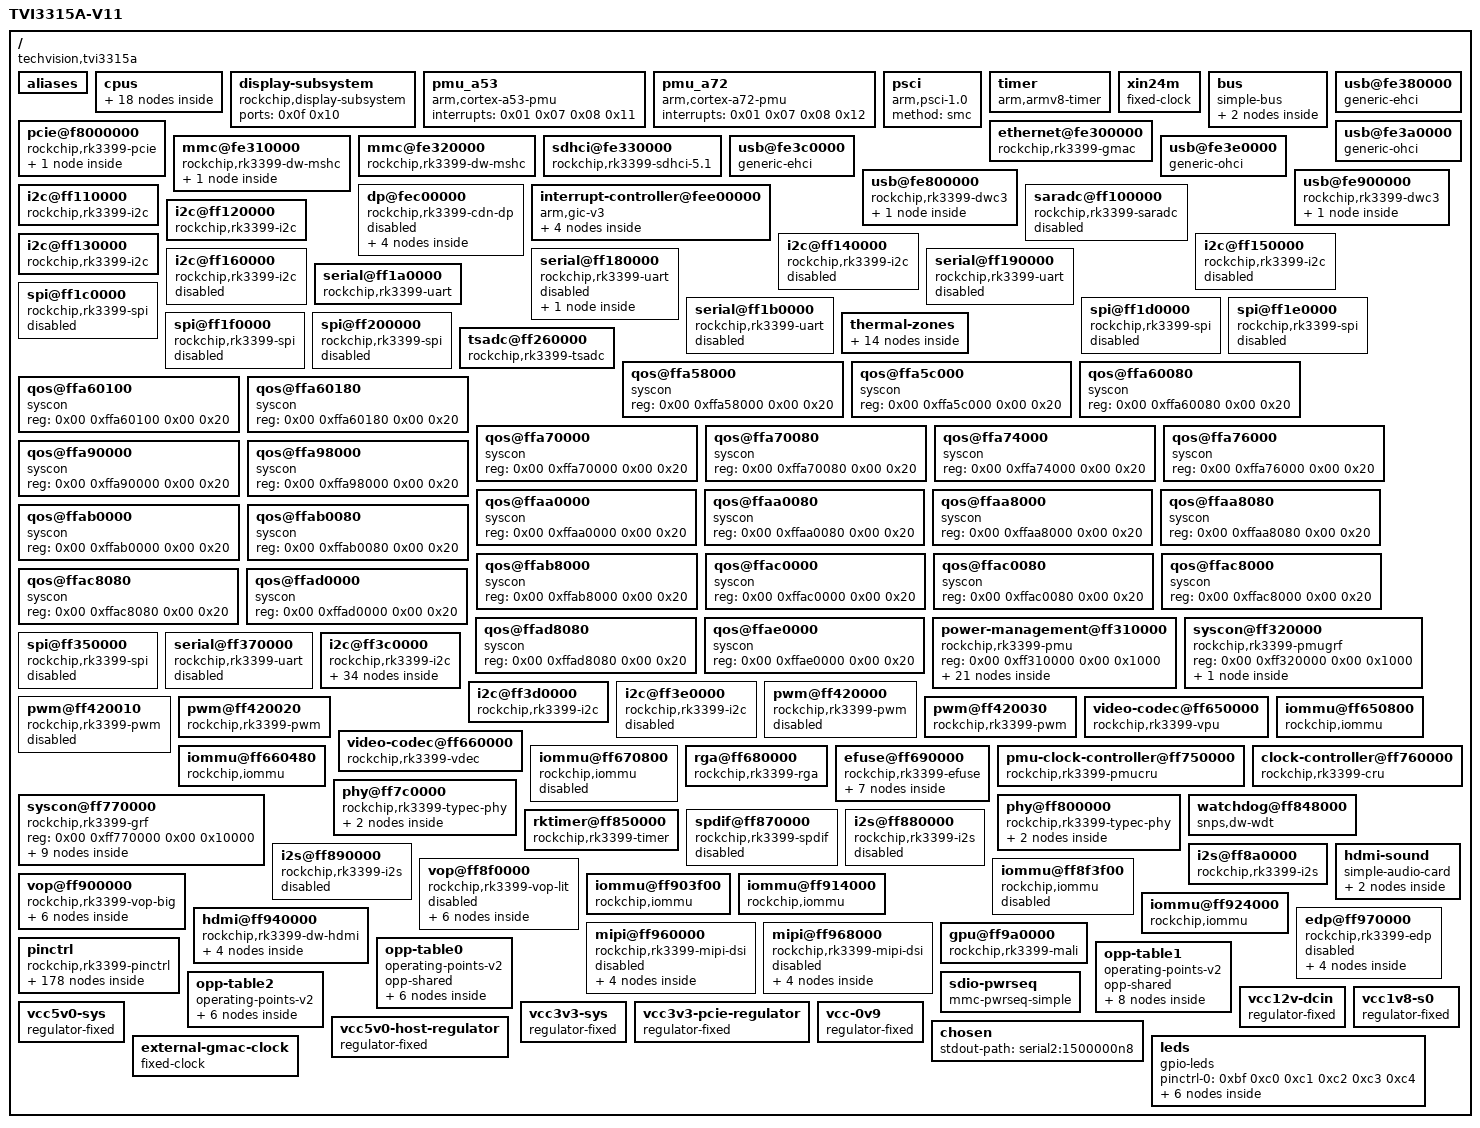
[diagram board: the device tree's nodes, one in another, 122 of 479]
/dts-v1/;

/ {
	compatible = "techvision,tvi3315a\0rockchip,rk3399";
	interrupt-parent = <0x01>;
	#address-cells = <0x02>;
	#size-cells = <0x02>;
	model = "TVI3315A-V11";

	aliases {
		ethernet0 = "/ethernet@fe300000";
		i2c0 = "/i2c@ff3c0000";
		i2c1 = "/i2c@ff110000";
		i2c2 = "/i2c@ff120000";
		i2c3 = "/i2c@ff130000";
		i2c4 = "/i2c@ff3d0000";
		i2c5 = "/i2c@ff140000";
		i2c6 = "/i2c@ff150000";
		i2c7 = "/i2c@ff160000";
		i2c8 = "/i2c@ff3e0000";
		serial0 = "/serial@ff180000";
		serial1 = "/serial@ff190000";
		serial2 = "/serial@ff1a0000";
		serial3 = "/serial@ff1b0000";
		serial4 = "/serial@ff370000";
	};

	cpus {
		#address-cells = <0x02>;
		#size-cells = <0x00>;

		cpu-map {

			cluster0 {

				core0 {
					cpu = <0x02>;
				};

				core1 {
					cpu = <0x03>;
				};

				core2 {
					cpu = <0x04>;
				};

				core3 {
					cpu = <0x05>;
				};
			};

			cluster1 {

				core0 {
					cpu = <0x06>;
				};

				core1 {
					cpu = <0x07>;
				};
			};
		};

		cpu@0 {
			device_type = "cpu";
			compatible = "arm,cortex-a53";
			reg = <0x00 0x00>;
			enable-method = "psci";
			capacity-dmips-mhz = <0x1e5>;
			clocks = <0x08 0x08>;
			#cooling-cells = <0x02>;
			dynamic-power-coefficient = <0x64>;
			cpu-idle-states = <0x09 0x0a>;
			operating-points-v2 = <0x0b>;
			cpu-supply = <0x0c>;
			phandle = <0x02>;
		};

		cpu@1 {
			device_type = "cpu";
			compatible = "arm,cortex-a53";
			reg = <0x00 0x01>;
			enable-method = "psci";
			capacity-dmips-mhz = <0x1e5>;
			clocks = <0x08 0x08>;
			#cooling-cells = <0x02>;
			dynamic-power-coefficient = <0x64>;
			cpu-idle-states = <0x09 0x0a>;
			operating-points-v2 = <0x0b>;
			cpu-supply = <0x0c>;
			phandle = <0x03>;
		};

		cpu@2 {
			device_type = "cpu";
			compatible = "arm,cortex-a53";
			reg = <0x00 0x02>;
			enable-method = "psci";
			capacity-dmips-mhz = <0x1e5>;
			clocks = <0x08 0x08>;
			#cooling-cells = <0x02>;
			dynamic-power-coefficient = <0x64>;
			cpu-idle-states = <0x09 0x0a>;
			operating-points-v2 = <0x0b>;
			cpu-supply = <0x0c>;
			phandle = <0x04>;
		};

		cpu@3 {
			device_type = "cpu";
			compatible = "arm,cortex-a53";
			reg = <0x00 0x03>;
			enable-method = "psci";
			capacity-dmips-mhz = <0x1e5>;
			clocks = <0x08 0x08>;
			#cooling-cells = <0x02>;
			dynamic-power-coefficient = <0x64>;
			cpu-idle-states = <0x09 0x0a>;
			operating-points-v2 = <0x0b>;
			cpu-supply = <0x0c>;
			phandle = <0x05>;
		};

		cpu@100 {
			device_type = "cpu";
			compatible = "arm,cortex-a72";
			reg = <0x00 0x100>;
			enable-method = "psci";
			capacity-dmips-mhz = <0x400>;
			clocks = <0x08 0x09>;
			#cooling-cells = <0x02>;
			dynamic-power-coefficient = <0x1b4>;
			cpu-idle-states = <0x09 0x0a>;
			operating-points-v2 = <0x0d>;
			cpu-supply = <0x0e>;
			phandle = <0x06>;
		};

		cpu@101 {
			device_type = "cpu";
			compatible = "arm,cortex-a72";
			reg = <0x00 0x101>;
			enable-method = "psci";
			capacity-dmips-mhz = <0x400>;
			clocks = <0x08 0x09>;
			#cooling-cells = <0x02>;
			dynamic-power-coefficient = <0x1b4>;
			cpu-idle-states = <0x09 0x0a>;
			operating-points-v2 = <0x0d>;
			cpu-supply = <0x0e>;
			phandle = <0x07>;
		};

		idle-states {
			entry-method = "psci";

			cpu-sleep {
				compatible = "arm,idle-state";
				local-timer-stop;
				arm,psci-suspend-param = <0x10000>;
				entry-latency-us = <0x78>;
				exit-latency-us = <0xfa>;
				min-residency-us = <0x384>;
				phandle = <0x09>;
			};

			cluster-sleep {
				compatible = "arm,idle-state";
				local-timer-stop;
				arm,psci-suspend-param = <0x1010000>;
				entry-latency-us = <0x190>;
				exit-latency-us = <0x1f4>;
				min-residency-us = <0x7d0>;
				phandle = <0x0a>;
			};
		};
	};

	display-subsystem {
		compatible = "rockchip,display-subsystem";
		ports = <0x0f 0x10>;
	};

	pmu_a53 {
		compatible = "arm,cortex-a53-pmu";
		interrupts = <0x01 0x07 0x08 0x11>;
	};

	pmu_a72 {
		compatible = "arm,cortex-a72-pmu";
		interrupts = <0x01 0x07 0x08 0x12>;
	};

	psci {
		compatible = "arm,psci-1.0";
		method = "smc";
	};

	timer {
		compatible = "arm,armv8-timer";
		interrupts = <0x01 0x0d 0x08 0x00 0x01 0x0e 0x08 0x00 0x01 0x0b 0x08 0x00 0x01 0x0a 0x08 0x00>;
		arm,no-tick-in-suspend;
	};

	xin24m {
		compatible = "fixed-clock";
		clock-frequency = <0x16e3600>;
		clock-output-names = "xin24m";
		#clock-cells = <0x00>;
	};

	bus {
		compatible = "simple-bus";
		#address-cells = <0x02>;
		#size-cells = <0x02>;
		ranges;

		dma-controller@ff6d0000 {
			compatible = "arm,pl330\0arm,primecell";
			reg = <0x00 0xff6d0000 0x00 0x4000>;
			interrupts = <0x00 0x05 0x04 0x00 0x00 0x06 0x04 0x00>;
			#dma-cells = <0x01>;
			clocks = <0x08 0xd3>;
			clock-names = "apb_pclk";
			phandle = <0x5a>;
		};

		dma-controller@ff6e0000 {
			compatible = "arm,pl330\0arm,primecell";
			reg = <0x00 0xff6e0000 0x00 0x4000>;
			interrupts = <0x00 0x07 0x04 0x00 0x00 0x08 0x04 0x00>;
			#dma-cells = <0x01>;
			clocks = <0x08 0xd4>;
			clock-names = "apb_pclk";
			phandle = <0x49>;
		};
	};

	pcie@f8000000 {
		compatible = "rockchip,rk3399-pcie";
		reg = <0x00 0xf8000000 0x00 0x2000000 0x00 0xfd000000 0x00 0x1000000>;
		reg-names = "axi-base\0apb-base";
		#address-cells = <0x03>;
		#size-cells = <0x02>;
		#interrupt-cells = <0x01>;
		aspm-no-l0s;
		bus-range = <0x00 0x1f>;
		clocks = <0x08 0xc5 0x08 0xc4 0x08 0x147 0x08 0xa0>;
		clock-names = "aclk\0aclk-perf\0hclk\0pm";
		interrupts = <0x00 0x31 0x04 0x00 0x00 0x32 0x04 0x00 0x00 0x33 0x04 0x00>;
		interrupt-names = "sys\0legacy\0client";
		interrupt-map-mask = <0x00 0x00 0x00 0x07>;
		interrupt-map = <0x00 0x00 0x00 0x01 0x13 0x00 0x00 0x00 0x00 0x02 0x13 0x01 0x00 0x00 0x00 0x03 0x13 0x02 0x00 0x00 0x00 0x04 0x13 0x03>;
		linux,pci-domain = <0x00>;
		max-link-speed = <0x01>;
		msi-map = <0x00 0x14 0x00 0x1000>;
		phys = <0x15 0x00 0x15 0x01 0x15 0x02 0x15 0x03>;
		phy-names = "pcie-phy-0\0pcie-phy-1\0pcie-phy-2\0pcie-phy-3";
		ranges = <0x83000000 0x00 0xfa000000 0x00 0xfa000000 0x00 0x1e00000 0x81000000 0x00 0xfbe00000 0x00 0xfbe00000 0x00 0x100000>;
		resets = <0x08 0x82 0x08 0x83 0x08 0x84 0x08 0x85 0x08 0x86 0x08 0x81 0x08 0x80>;
		reset-names = "core\0mgmt\0mgmt-sticky\0pipe\0pm\0pclk\0aclk";
		status = "okay";
		num-lanes = <0x04>;
		pinctrl-names = "default";
		pinctrl-0 = <0x16>;
		vpcie0v9-supply = <0x17>;
		vpcie1v8-supply = <0x18>;
		vpcie3v3-supply = <0x19>;
		ep-gpios = <0x1a 0x02 0x00>;

		interrupt-controller {
			interrupt-controller;
			#address-cells = <0x00>;
			#interrupt-cells = <0x01>;
			phandle = <0x13>;
		};
	};

	ethernet@fe300000 {
		compatible = "rockchip,rk3399-gmac";
		reg = <0x00 0xfe300000 0x00 0x10000>;
		interrupts = <0x00 0x0c 0x04 0x00>;
		interrupt-names = "macirq";
		clocks = <0x08 0x69 0x08 0x67 0x08 0x68 0x08 0x66 0x08 0x6a 0x08 0xd5 0x08 0x166>;
		clock-names = "stmmaceth\0mac_clk_rx\0mac_clk_tx\0clk_mac_ref\0clk_mac_refout\0aclk_mac\0pclk_mac";
		power-domains = <0x1b 0x16>;
		resets = <0x08 0x89>;
		reset-names = "stmmaceth";
		rockchip,grf = <0x1c>;
		snps,txpbl = <0x04>;
		status = "okay";
		assigned-clocks = <0x08 0xa6>;
		assigned-clock-parents = <0x1d>;
		clock_in_out = "input";
		phy-supply = <0x1e>;
		phy-mode = "rgmii";
		pinctrl-names = "default";
		pinctrl-0 = <0x1f>;
		snps,reset-gpio = <0x20 0x0f 0x01>;
		snps,reset-active-low;
		snps,reset-delays-us = <0x00 0x2710 0xc350>;
		tx_delay = <0x2a>;
		rx_delay = <0x21>;
	};

	mmc@fe310000 {
		compatible = "rockchip,rk3399-dw-mshc\0rockchip,rk3288-dw-mshc";
		reg = <0x00 0xfe310000 0x00 0x4000>;
		interrupts = <0x00 0x40 0x04 0x00>;
		max-frequency = <0x8f0d180>;
		clocks = <0x08 0x1ee 0x08 0x4d 0x08 0x9c 0x08 0x9d>;
		clock-names = "biu\0ciu\0ciu-drive\0ciu-sample";
		fifo-depth = <0x100>;
		power-domains = <0x1b 0x1c>;
		resets = <0x08 0x79>;
		reset-names = "reset";
		status = "okay";
		bus-width = <0x04>;
		clock-frequency = <0x2faf080>;
		cap-sdio-irq;
		cap-sd-highspeed;
		keep-power-in-suspend;
		mmc-pwrseq = <0x21>;
		non-removable;
		pinctrl-names = "default";
		pinctrl-0 = <0x22 0x23 0x24>;
		sd-uhs-sdr104;
		#address-cells = <0x01>;
		#size-cells = <0x00>;

		wifi@1 {
			compatible = "brcm,bcm43455-fmac";
			reg = <0x01>;
			interrupt-parent = <0x25>;
			interrupts = <0x03 0x00>;
			interrupt-names = "host-wake";
			pinctrl-names = "default";
			pinctrl-0 = <0x26>;
		};
	};

	mmc@fe320000 {
		compatible = "rockchip,rk3399-dw-mshc\0rockchip,rk3288-dw-mshc";
		reg = <0x00 0xfe320000 0x00 0x4000>;
		interrupts = <0x00 0x41 0x04 0x00>;
		max-frequency = <0x5f5e100>;
		assigned-clocks = <0x08 0x1cd>;
		assigned-clock-rates = <0xbebc200>;
		clocks = <0x08 0x1ce 0x08 0x4c 0x08 0x9a 0x08 0x9b>;
		clock-names = "biu\0ciu\0ciu-drive\0ciu-sample";
		fifo-depth = <0x100>;
		power-domains = <0x1b 0x1b>;
		resets = <0x08 0x7a>;
		reset-names = "reset";
		status = "okay";
		bus-width = <0x04>;
		cap-mmc-highspeed;
		cap-sd-highspeed;
		clock-frequency = <0x5f5e100>;
		cd-gpios = <0x25 0x07 0x01>;
		disable-wp;
		sd-uhs-sdr104;
		vqmmc-supply = <0x27>;
		card-detect-delay = <0x320>;
		pinctrl-names = "default";
		pinctrl-0 = <0x28 0x29 0x2a 0x2b>;
	};

	sdhci@fe330000 {
		compatible = "rockchip,rk3399-sdhci-5.1\0arasan,sdhci-5.1";
		reg = <0x00 0xfe330000 0x00 0x10000>;
		interrupts = <0x00 0x0b 0x04 0x00>;
		arasan,soc-ctl-syscon = <0x1c>;
		assigned-clocks = <0x08 0x4e>;
		assigned-clock-rates = <0xbebc200>;
		clocks = <0x08 0x4e 0x08 0xf0>;
		clock-names = "clk_xin\0clk_ahb";
		clock-output-names = "emmc_cardclock";
		#clock-cells = <0x00>;
		phys = <0x2c>;
		phy-names = "phy_arasan";
		power-domains = <0x1b 0x17>;
		disable-cqe-dcmd;
		status = "okay";
		bus-width = <0x08>;
		mmc-hs400-1_8v;
		mmc-hs400-enhanced-strobe;
		non-removable;
		phandle = <0x91>;
	};

	usb@fe380000 {
		compatible = "generic-ehci";
		reg = <0x00 0xfe380000 0x00 0x20000>;
		interrupts = <0x00 0x1a 0x04 0x00>;
		clocks = <0x08 0x1c8 0x08 0x1c9 0x2d>;
		phys = <0x2e>;
		phy-names = "usb";
		status = "okay";
	};

	usb@fe3a0000 {
		compatible = "generic-ohci";
		reg = <0x00 0xfe3a0000 0x00 0x20000>;
		interrupts = <0x00 0x1c 0x04 0x00>;
		clocks = <0x08 0x1c8 0x08 0x1c9 0x2d>;
		phys = <0x2e>;
		phy-names = "usb";
		status = "okay";
	};

	usb@fe3c0000 {
		compatible = "generic-ehci";
		reg = <0x00 0xfe3c0000 0x00 0x20000>;
		interrupts = <0x00 0x1e 0x04 0x00>;
		clocks = <0x08 0x1ca 0x08 0x1cb 0x2f>;
		phys = <0x30>;
		phy-names = "usb";
		status = "okay";
	};

	usb@fe3e0000 {
		compatible = "generic-ohci";
		reg = <0x00 0xfe3e0000 0x00 0x20000>;
		interrupts = <0x00 0x20 0x04 0x00>;
		clocks = <0x08 0x1ca 0x08 0x1cb 0x2f>;
		phys = <0x30>;
		phy-names = "usb";
		status = "okay";
	};

	usb@fe800000 {
		compatible = "rockchip,rk3399-dwc3";
		#address-cells = <0x02>;
		#size-cells = <0x02>;
		ranges;
		clocks = <0x08 0x81 0x08 0x83 0x08 0xf6 0x08 0xf8 0x08 0xf4 0x08 0xf9>;
		clock-names = "ref_clk\0suspend_clk\0bus_clk\0aclk_usb3_rksoc_axi_perf\0aclk_usb3\0grf_clk";
		resets = <0x08 0x125>;
		reset-names = "usb3-otg";
		status = "okay";

		usb@fe800000 {
			compatible = "snps,dwc3";
			reg = <0x00 0xfe800000 0x00 0x100000>;
			interrupts = <0x00 0x69 0x04 0x00>;
			clocks = <0x08 0x81 0x08 0xf6 0x08 0x83>;
			clock-names = "ref\0bus_early\0suspend";
			dr_mode = "host";
			phys = <0x31 0x32>;
			phy-names = "usb2-phy\0usb3-phy";
			phy_type = "utmi_wide";
			snps,dis_enblslpm_quirk;
			snps,dis-u2-freeclk-exists-quirk;
			snps,dis_u2_susphy_quirk;
			snps,dis-del-phy-power-chg-quirk;
			snps,dis-tx-ipgap-linecheck-quirk;
			power-domains = <0x1b 0x18>;
			status = "okay";
		};
	};

	usb@fe900000 {
		compatible = "rockchip,rk3399-dwc3";
		#address-cells = <0x02>;
		#size-cells = <0x02>;
		ranges;
		clocks = <0x08 0x82 0x08 0x84 0x08 0xf7 0x08 0xf8 0x08 0xf4 0x08 0xf9>;
		clock-names = "ref_clk\0suspend_clk\0bus_clk\0aclk_usb3_rksoc_axi_perf\0aclk_usb3\0grf_clk";
		resets = <0x08 0x126>;
		reset-names = "usb3-otg";
		status = "okay";

		usb@fe900000 {
			compatible = "snps,dwc3";
			reg = <0x00 0xfe900000 0x00 0x100000>;
			interrupts = <0x00 0x6e 0x04 0x00>;
			clocks = <0x08 0x82 0x08 0xf7 0x08 0x84>;
			clock-names = "ref\0bus_early\0suspend";
			dr_mode = "host";
			phys = <0x33 0x34>;
			phy-names = "usb2-phy\0usb3-phy";
			phy_type = "utmi_wide";
			snps,dis_enblslpm_quirk;
			snps,dis-u2-freeclk-exists-quirk;
			snps,dis_u2_susphy_quirk;
			snps,dis-del-phy-power-chg-quirk;
			snps,dis-tx-ipgap-linecheck-quirk;
			power-domains = <0x1b 0x18>;
			status = "okay";
		};
	};

	dp@fec00000 {
		compatible = "rockchip,rk3399-cdn-dp";
		reg = <0x00 0xfec00000 0x00 0x100000>;
		interrupts = <0x00 0x09 0x04 0x00>;
		assigned-clocks = <0x08 0x72 0x08 0xa1>;
		assigned-clock-rates = <0x5f5e100 0xbebc200>;
		clocks = <0x08 0x72 0x08 0x175 0x08 0xa1 0x08 0x16f>;
		clock-names = "core-clk\0pclk\0spdif\0grf";
		phys = <0x35 0x36>;
		power-domains = <0x1b 0x15>;
		resets = <0x08 0x103 0x08 0x148 0x08 0x14a 0x08 0xfd>;
		reset-names = "spdif\0dptx\0apb\0core";
		rockchip,grf = <0x1c>;
		#sound-dai-cells = <0x01>;
		status = "disabled";

		ports {

			port {
				#address-cells = <0x01>;
				#size-cells = <0x00>;

				endpoint@0 {
					reg = <0x00>;
					remote-endpoint = <0x37>;
					phandle = <0xa0>;
				};

				endpoint@1 {
					reg = <0x01>;
					remote-endpoint = <0x38>;
					phandle = <0x9a>;
				};
			};
		};
	};

	interrupt-controller@fee00000 {
		compatible = "arm,gic-v3";
		#interrupt-cells = <0x04>;
		#address-cells = <0x02>;
		#size-cells = <0x02>;
		ranges;
		interrupt-controller;
		reg = <0x00 0xfee00000 0x00 0x10000 0x00 0xfef00000 0x00 0xc0000 0x00 0xfff00000 0x00 0x10000 0x00 0xfff10000 0x00 0x10000 0x00 0xfff20000 0x00 0x10000>;
		interrupts = <0x01 0x09 0x04 0x00>;
		phandle = <0x01>;

		interrupt-controller@fee20000 {
			compatible = "arm,gic-v3-its";
			msi-controller;
			#msi-cells = <0x01>;
			reg = <0x00 0xfee20000 0x00 0x20000>;
			phandle = <0x14>;
		};

		ppi-partitions {

			interrupt-partition-0 {
				affinity = <0x02 0x03 0x04 0x05>;
				phandle = <0x11>;
			};

			interrupt-partition-1 {
				affinity = <0x06 0x07>;
				phandle = <0x12>;
			};
		};
	};

	saradc@ff100000 {
		compatible = "rockchip,rk3399-saradc";
		reg = <0x00 0xff100000 0x00 0x100>;
		interrupts = <0x00 0x3e 0x04 0x00>;
		#io-channel-cells = <0x01>;
		clocks = <0x08 0x50 0x08 0x165>;
		clock-names = "saradc\0apb_pclk";
		resets = <0x08 0xd4>;
		reset-names = "saradc-apb";
		status = "disabled";
	};

	i2c@ff110000 {
		compatible = "rockchip,rk3399-i2c";
		reg = <0x00 0xff110000 0x00 0x1000>;
		assigned-clocks = <0x08 0x41>;
		assigned-clock-rates = <0xbebc200>;
		clocks = <0x08 0x41 0x08 0x155>;
		clock-names = "i2c\0pclk";
		interrupts = <0x00 0x3b 0x04 0x00>;
		pinctrl-names = "default";
		pinctrl-0 = <0x39>;
		#address-cells = <0x01>;
		#size-cells = <0x00>;
		status = "okay";
	};

	i2c@ff120000 {
		compatible = "rockchip,rk3399-i2c";
		reg = <0x00 0xff120000 0x00 0x1000>;
		assigned-clocks = <0x08 0x42>;
		assigned-clock-rates = <0xbebc200>;
		clocks = <0x08 0x42 0x08 0x156>;
		clock-names = "i2c\0pclk";
		interrupts = <0x00 0x23 0x04 0x00>;
		pinctrl-names = "default";
		pinctrl-0 = <0x3a>;
		#address-cells = <0x01>;
		#size-cells = <0x00>;
		status = "okay";
	};

	i2c@ff130000 {
		compatible = "rockchip,rk3399-i2c";
		reg = <0x00 0xff130000 0x00 0x1000>;
		assigned-clocks = <0x08 0x43>;
		assigned-clock-rates = <0xbebc200>;
		clocks = <0x08 0x43 0x08 0x157>;
		clock-names = "i2c\0pclk";
		interrupts = <0x00 0x22 0x04 0x00>;
		pinctrl-names = "default";
		pinctrl-0 = <0x3b>;
		#address-cells = <0x01>;
		#size-cells = <0x00>;
		status = "okay";
		phandle = <0xa3>;
	};

	i2c@ff140000 {
		compatible = "rockchip,rk3399-i2c";
		reg = <0x00 0xff140000 0x00 0x1000>;
		assigned-clocks = <0x08 0x44>;
		assigned-clock-rates = <0xbebc200>;
		clocks = <0x08 0x44 0x08 0x158>;
		clock-names = "i2c\0pclk";
		interrupts = <0x00 0x26 0x04 0x00>;
		pinctrl-names = "default";
		pinctrl-0 = <0x3c>;
		#address-cells = <0x01>;
		#size-cells = <0x00>;
		status = "disabled";
	};

	i2c@ff150000 {
		compatible = "rockchip,rk3399-i2c";
		reg = <0x00 0xff150000 0x00 0x1000>;
		assigned-clocks = <0x08 0x45>;
		assigned-clock-rates = <0xbebc200>;
		clocks = <0x08 0x45 0x08 0x159>;
		clock-names = "i2c\0pclk";
		interrupts = <0x00 0x25 0x04 0x00>;
		pinctrl-names = "default";
		pinctrl-0 = <0x3d>;
		#address-cells = <0x01>;
		#size-cells = <0x00>;
		status = "disabled";
	};

	i2c@ff160000 {
		compatible = "rockchip,rk3399-i2c";
		reg = <0x00 0xff160000 0x00 0x1000>;
		assigned-clocks = <0x08 0x46>;
		assigned-clock-rates = <0xbebc200>;
		clocks = <0x08 0x46 0x08 0x15a>;
		clock-names = "i2c\0pclk";
		interrupts = <0x00 0x24 0x04 0x00>;
		pinctrl-names = "default";
		pinctrl-0 = <0x3e>;
		#address-cells = <0x01>;
		#size-cells = <0x00>;
		status = "disabled";
	};

	serial@ff180000 {
		compatible = "rockchip,rk3399-uart\0snps,dw-apb-uart";
		reg = <0x00 0xff180000 0x00 0x100>;
		clocks = <0x08 0x51 0x08 0x160>;
		clock-names = "baudclk\0apb_pclk";
		interrupts = <0x00 0x63 0x04 0x00>;
		reg-shift = <0x02>;
		reg-io-width = <0x04>;
		pinctrl-names = "default";
		pinctrl-0 = <0x3f 0x40 0x41>;
		status = "disabled";

		bluetooth {
			compatible = "brcm,bcm4345c5";
			clocks = <0x42 0x01>;
			clock-names = "ext_clock";
			device-wakeup-gpios = <0x1a 0x1b 0x00>;
			host-wakeup-gpios = <0x25 0x04 0x00>;
			shutdown-gpios = <0x25 0x0b 0x00>;
			max-speed = <0x16e360>;
			pinctrl-names = "default";
			pinctrl-0 = <0x43 0x44 0x45>;
		};
	};

	serial@ff190000 {
		compatible = "rockchip,rk3399-uart\0snps,dw-apb-uart";
		reg = <0x00 0xff190000 0x00 0x100>;
		clocks = <0x08 0x52 0x08 0x161>;
		clock-names = "baudclk\0apb_pclk";
		interrupts = <0x00 0x62 0x04 0x00>;
		reg-shift = <0x02>;
		reg-io-width = <0x04>;
		pinctrl-names = "default";
		pinctrl-0 = <0x46>;
		status = "disabled";
	};

	serial@ff1a0000 {
		compatible = "rockchip,rk3399-uart\0snps,dw-apb-uart";
		reg = <0x00 0xff1a0000 0x00 0x100>;
		clocks = <0x08 0x53 0x08 0x162>;
		clock-names = "baudclk\0apb_pclk";
		interrupts = <0x00 0x64 0x04 0x00>;
		reg-shift = <0x02>;
		reg-io-width = <0x04>;
		pinctrl-names = "default";
		pinctrl-0 = <0x47>;
		status = "okay";
	};

	serial@ff1b0000 {
		compatible = "rockchip,rk3399-uart\0snps,dw-apb-uart";
		reg = <0x00 0xff1b0000 0x00 0x100>;
		clocks = <0x08 0x54 0x08 0x163>;
		clock-names = "baudclk\0apb_pclk";
		interrupts = <0x00 0x65 0x04 0x00>;
		reg-shift = <0x02>;
		reg-io-width = <0x04>;
		pinctrl-names = "default";
		pinctrl-0 = <0x48>;
		status = "disabled";
	};

	spi@ff1c0000 {
		compatible = "rockchip,rk3399-spi\0rockchip,rk3066-spi";
		reg = <0x00 0xff1c0000 0x00 0x1000>;
		clocks = <0x08 0x47 0x08 0x15b>;
		clock-names = "spiclk\0apb_pclk";
		interrupts = <0x00 0x44 0x04 0x00>;
		dmas = <0x49 0x0a 0x49 0x0b>;
		dma-names = "tx\0rx";
		pinctrl-names = "default";
		pinctrl-0 = <0x4a 0x4b 0x4c 0x4d>;
		#address-cells = <0x01>;
		#size-cells = <0x00>;
		status = "disabled";
	};

	spi@ff1d0000 {
		compatible = "rockchip,rk3399-spi\0rockchip,rk3066-spi";
		reg = <0x00 0xff1d0000 0x00 0x1000>;
		clocks = <0x08 0x48 0x08 0x15c>;
		clock-names = "spiclk\0apb_pclk";
		interrupts = <0x00 0x35 0x04 0x00>;
		dmas = <0x49 0x0c 0x49 0x0d>;
		dma-names = "tx\0rx";
		pinctrl-names = "default";
		pinctrl-0 = <0x4e 0x4f 0x50 0x51>;
		#address-cells = <0x01>;
		#size-cells = <0x00>;
		status = "disabled";
	};

	spi@ff1e0000 {
		compatible = "rockchip,rk3399-spi\0rockchip,rk3066-spi";
		reg = <0x00 0xff1e0000 0x00 0x1000>;
		clocks = <0x08 0x49 0x08 0x15d>;
		clock-names = "spiclk\0apb_pclk";
		interrupts = <0x00 0x34 0x04 0x00>;
		dmas = <0x49 0x0e 0x49 0x0f>;
		dma-names = "tx\0rx";
		pinctrl-names = "default";
		pinctrl-0 = <0x52 0x53 0x54 0x55>;
		#address-cells = <0x01>;
		#size-cells = <0x00>;
		status = "disabled";
	};

	spi@ff1f0000 {
		compatible = "rockchip,rk3399-spi\0rockchip,rk3066-spi";
		reg = <0x00 0xff1f0000 0x00 0x1000>;
		clocks = <0x08 0x4a 0x08 0x15e>;
		clock-names = "spiclk\0apb_pclk";
		interrupts = <0x00 0x43 0x04 0x00>;
		dmas = <0x49 0x12 0x49 0x13>;
		dma-names = "tx\0rx";
		pinctrl-names = "default";
		pinctrl-0 = <0x56 0x57 0x58 0x59>;
		#address-cells = <0x01>;
		#size-cells = <0x00>;
		status = "disabled";
	};

	spi@ff200000 {
		compatible = "rockchip,rk3399-spi\0rockchip,rk3066-spi";
		reg = <0x00 0xff200000 0x00 0x1000>;
		clocks = <0x08 0x4b 0x08 0x15f>;
		clock-names = "spiclk\0apb_pclk";
		interrupts = <0x00 0x84 0x04 0x00>;
		dmas = <0x5a 0x08 0x5a 0x09>;
		dma-names = "tx\0rx";
		pinctrl-names = "default";
		pinctrl-0 = <0x5b 0x5c 0x5d 0x5e>;
		power-domains = <0x1b 0x1c>;
		#address-cells = <0x01>;
		#size-cells = <0x00>;
		status = "disabled";
	};

	thermal-zones {

		cpu {
			polling-delay-passive = <0x64>;
			polling-delay = <0x3e8>;
			thermal-sensors = <0x5f 0x00>;
			sustainable-power = <0x60e>;

			trips {

				cpu_alert0 {
					temperature = <0xfde8>;
					hysteresis = <0x7d0>;
					type = "passive";
				};

				cpu_alert1 {
					temperature = <0x124f8>;
					hysteresis = <0x7d0>;
					type = "passive";
					phandle = <0x60>;
				};

				cpu_crit {
					temperature = <0x17318>;
					hysteresis = <0x7d0>;
					type = "critical";
				};
			};

			cooling-maps {

				map0 {
					trip = <0x60>;
					cooling-device = <0x06 0xffffffff 0xffffffff 0x07 0xffffffff 0xffffffff>;
				};

				map1 {
					trip = <0x60>;
					cooling-device = <0x02 0xffffffff 0xffffffff 0x03 0xffffffff 0xffffffff 0x04 0xffffffff 0xffffffff 0x05 0xffffffff 0xffffffff 0x06 0xffffffff 0xffffffff 0x07 0xffffffff 0xffffffff>;
				};
			};
		};

		gpu {
			polling-delay-passive = <0x64>;
			polling-delay = <0x3e8>;
			thermal-sensors = <0x5f 0x01>;

			trips {

				gpu_alert0 {
					temperature = <0x124f8>;
					hysteresis = <0x7d0>;
					type = "passive";
					phandle = <0x61>;
				};

				gpu_crit {
					temperature = <0x17318>;
					hysteresis = <0x7d0>;
					type = "critical";
				};
			};

			cooling-maps {

				map0 {
					trip = <0x61>;
					cooling-device = <0x62 0xffffffff 0xffffffff>;
				};
			};
		};
	};

	tsadc@ff260000 {
		compatible = "rockchip,rk3399-tsadc";
		reg = <0x00 0xff260000 0x00 0x100>;
		interrupts = <0x00 0x61 0x04 0x00>;
		assigned-clocks = <0x08 0x4f>;
		assigned-clock-rates = <0xb71b0>;
		clocks = <0x08 0x4f 0x08 0x164>;
		clock-names = "tsadc\0apb_pclk";
		resets = <0x08 0xe8>;
		reset-names = "tsadc-apb";
		rockchip,grf = <0x1c>;
		rockchip,hw-tshut-temp = <0x1adb0>;
		pinctrl-names = "init\0default\0sleep";
		pinctrl-0 = <0x63>;
		pinctrl-1 = <0x64>;
		pinctrl-2 = <0x63>;
		#thermal-sensor-cells = <0x01>;
		status = "okay";
		rockchip,hw-tshut-mode = <0x01>;
		rockchip,hw-tshut-polarity = <0x01>;
		phandle = <0x5f>;
	};

	qos@ffa58000 {
		compatible = "syscon";
		reg = <0x00 0xffa58000 0x00 0x20>;
		phandle = <0x6c>;
	};

	qos@ffa5c000 {
		compatible = "syscon";
		reg = <0x00 0xffa5c000 0x00 0x20>;
		phandle = <0x6d>;
	};

	qos@ffa60080 {
		compatible = "syscon";
		reg = <0x00 0xffa60080 0x00 0x20>;
	};

	qos@ffa60100 {
		compatible = "syscon";
		reg = <0x00 0xffa60100 0x00 0x20>;
	};

	qos@ffa60180 {
		compatible = "syscon";
		reg = <0x00 0xffa60180 0x00 0x20>;
	};

	qos@ffa70000 {
		compatible = "syscon";
		reg = <0x00 0xffa70000 0x00 0x20>;
		phandle = <0x70>;
	};

	qos@ffa70080 {
		compatible = "syscon";
		reg = <0x00 0xffa70080 0x00 0x20>;
		phandle = <0x71>;
	};

	qos@ffa74000 {
		compatible = "syscon";
		reg = <0x00 0xffa74000 0x00 0x20>;
		phandle = <0x6e>;
	};

	qos@ffa76000 {
		compatible = "syscon";
		reg = <0x00 0xffa76000 0x00 0x20>;
		phandle = <0x6f>;
	};

	qos@ffa90000 {
		compatible = "syscon";
		reg = <0x00 0xffa90000 0x00 0x20>;
		phandle = <0x72>;
	};

	qos@ffa98000 {
		compatible = "syscon";
		reg = <0x00 0xffa98000 0x00 0x20>;
		phandle = <0x65>;
	};

	qos@ffaa0000 {
		compatible = "syscon";
		reg = <0x00 0xffaa0000 0x00 0x20>;
		phandle = <0x73>;
	};

	qos@ffaa0080 {
		compatible = "syscon";
		reg = <0x00 0xffaa0080 0x00 0x20>;
		phandle = <0x74>;
	};

	qos@ffaa8000 {
		compatible = "syscon";
		reg = <0x00 0xffaa8000 0x00 0x20>;
		phandle = <0x75>;
	};

	qos@ffaa8080 {
		compatible = "syscon";
		reg = <0x00 0xffaa8080 0x00 0x20>;
		phandle = <0x76>;
	};

	qos@ffab0000 {
		compatible = "syscon";
		reg = <0x00 0xffab0000 0x00 0x20>;
		phandle = <0x66>;
	};

	qos@ffab0080 {
		compatible = "syscon";
		reg = <0x00 0xffab0080 0x00 0x20>;
		phandle = <0x67>;
	};

	qos@ffab8000 {
		compatible = "syscon";
		reg = <0x00 0xffab8000 0x00 0x20>;
		phandle = <0x68>;
	};

	qos@ffac0000 {
		compatible = "syscon";
		reg = <0x00 0xffac0000 0x00 0x20>;
		phandle = <0x69>;
	};

	qos@ffac0080 {
		compatible = "syscon";
		reg = <0x00 0xffac0080 0x00 0x20>;
		phandle = <0x6a>;
	};

	qos@ffac8000 {
		compatible = "syscon";
		reg = <0x00 0xffac8000 0x00 0x20>;
		phandle = <0x77>;
	};

	qos@ffac8080 {
		compatible = "syscon";
		reg = <0x00 0xffac8080 0x00 0x20>;
		phandle = <0x78>;
	};

	qos@ffad0000 {
		compatible = "syscon";
		reg = <0x00 0xffad0000 0x00 0x20>;
		phandle = <0x79>;
	};

	qos@ffad8080 {
		compatible = "syscon";
		reg = <0x00 0xffad8080 0x00 0x20>;
	};

	qos@ffae0000 {
		compatible = "syscon";
		reg = <0x00 0xffae0000 0x00 0x20>;
		phandle = <0x6b>;
	};

	power-management@ff310000 {
		compatible = "rockchip,rk3399-pmu\0syscon\0simple-mfd";
		reg = <0x00 0xff310000 0x00 0x1000>;

		power-controller {
			compatible = "rockchip,rk3399-power-controller";
			#power-domain-cells = <0x01>;
			#address-cells = <0x01>;
			#size-cells = <0x00>;
			phandle = <0x1b>;

			pd_iep@34 {
				reg = <0x22>;
				clocks = <0x08 0xe1 0x08 0x1dd>;
				pm_qos = <0x65>;
			};

			pd_rga@33 {
				reg = <0x21>;
				clocks = <0x08 0xdc 0x08 0x1e5>;
				pm_qos = <0x66 0x67>;
			};

			pd_vcodec@31 {
				reg = <0x1f>;
				clocks = <0x08 0xeb 0x08 0x1ea>;
				pm_qos = <0x68>;
			};

			pd_vdu@32 {
				reg = <0x20>;
				clocks = <0x08 0xed 0x08 0x1ec>;
				pm_qos = <0x69 0x6a>;
			};

			pd_gpu@35 {
				reg = <0x23>;
				clocks = <0x08 0xd0>;
				pm_qos = <0x6b>;
			};

			pd_edp@25 {
				reg = <0x19>;
				clocks = <0x08 0x16c>;
			};

			pd_emmc@23 {
				reg = <0x17>;
				clocks = <0x08 0xf0>;
				pm_qos = <0x6c>;
			};

			pd_gmac@22 {
				reg = <0x16>;
				clocks = <0x08 0xd5 0x08 0x166>;
				pm_qos = <0x6d>;
			};

			pd_sd@27 {
				reg = <0x1b>;
				clocks = <0x08 0x1ce 0x08 0x4c>;
				pm_qos = <0x6e>;
			};

			pd_sdioaudio@28 {
				reg = <0x1c>;
				clocks = <0x08 0x1ee>;
				pm_qos = <0x6f>;
			};

			pd_usb3@24 {
				reg = <0x18>;
				clocks = <0x08 0xf4>;
				pm_qos = <0x70 0x71>;
			};

			pd_vio@15 {
				reg = <0x0f>;
				#address-cells = <0x01>;
				#size-cells = <0x00>;

				pd_hdcp@21 {
					reg = <0x15>;
					clocks = <0x08 0xde 0x08 0x1e7 0x08 0x172>;
					pm_qos = <0x72>;
				};

				pd_isp0@19 {
					reg = <0x13>;
					clocks = <0x08 0xe5 0x08 0x1df>;
					pm_qos = <0x73 0x74>;
				};

				pd_isp1@20 {
					reg = <0x14>;
					clocks = <0x08 0xe6 0x08 0x1e0>;
					pm_qos = <0x75 0x76>;
				};

				pd_tcpc0@RK3399_PD_TCPC0 {
					reg = <0x08>;
					clocks = <0x08 0x7e 0x08 0x7d>;
				};

				pd_tcpc1@RK3399_PD_TCPC1 {
					reg = <0x09>;
					clocks = <0x08 0x80 0x08 0x7f>;
				};

				pd_vo@16 {
					reg = <0x10>;
					#address-cells = <0x01>;
					#size-cells = <0x00>;

					pd_vopb@17 {
						reg = <0x11>;
						clocks = <0x08 0xd9 0x08 0x1d9>;
						pm_qos = <0x77 0x78>;
					};

					pd_vopl@18 {
						reg = <0x12>;
						clocks = <0x08 0xdb 0x08 0x1db>;
						pm_qos = <0x79>;
					};
				};
			};
		};
	};

	syscon@ff320000 {
		compatible = "rockchip,rk3399-pmugrf\0syscon\0simple-mfd";
		reg = <0x00 0xff320000 0x00 0x1000>;
		phandle = <0x8d>;

		io-domains {
			compatible = "rockchip,rk3399-pmu-io-voltage-domain";
			status = "okay";
			pmu1830-supply = <0x7a>;
		};
	};

	spi@ff350000 {
		compatible = "rockchip,rk3399-spi\0rockchip,rk3066-spi";
		reg = <0x00 0xff350000 0x00 0x1000>;
		clocks = <0x7b 0x03 0x7b 0x1f>;
		clock-names = "spiclk\0apb_pclk";
		interrupts = <0x00 0x3c 0x04 0x00>;
		pinctrl-names = "default";
		pinctrl-0 = <0x7c 0x7d 0x7e 0x7f>;
		#address-cells = <0x01>;
		#size-cells = <0x00>;
		status = "disabled";
	};

	serial@ff370000 {
		compatible = "rockchip,rk3399-uart\0snps,dw-apb-uart";
		reg = <0x00 0xff370000 0x00 0x100>;
		clocks = <0x7b 0x06 0x7b 0x22>;
		clock-names = "baudclk\0apb_pclk";
		interrupts = <0x00 0x66 0x04 0x00>;
		reg-shift = <0x02>;
		reg-io-width = <0x04>;
		pinctrl-names = "default";
		pinctrl-0 = <0x80>;
		status = "disabled";
	};

	i2c@ff3c0000 {
		compatible = "rockchip,rk3399-i2c";
		reg = <0x00 0xff3c0000 0x00 0x1000>;
		assigned-clocks = <0x7b 0x09>;
		assigned-clock-rates = <0xbebc200>;
		clocks = <0x7b 0x09 0x7b 0x1b>;
		clock-names = "i2c\0pclk";
		interrupts = <0x00 0x39 0x04 0x00>;
		pinctrl-names = "default";
		pinctrl-0 = <0x81>;
		#address-cells = <0x01>;
		#size-cells = <0x00>;
		status = "okay";
		clock-frequency = <0x61a80>;
		i2c-scl-rising-time-ns = <0xa8>;
		i2c-scl-falling-time-ns = <0x04>;

		regulator@40 {
			compatible = "silergy,syr827";
			reg = <0x40>;
			fcs,suspend-voltage-selector = <0x01>;
			regulator-name = "vdd_cpu_b";
			regulator-min-microvolt = <0xadf34>;
			regulator-max-microvolt = <0x16e360>;
			regulator-ramp-delay = <0x3e8>;
			regulator-always-on;
			regulator-boot-on;
			vin-supply = <0x82>;
			status = "okay";
			phandle = <0x0e>;

			regulator-state-mem {
				regulator-off-in-suspend;
			};
		};

		regulator@41 {
			compatible = "silergy,syr828";
			reg = <0x41>;
			fcs,suspend-voltage-selector = <0x01>;
			regulator-name = "vdd_gpu";
			regulator-min-microvolt = <0xadf34>;
			regulator-max-microvolt = <0x16e360>;
			regulator-ramp-delay = <0x3e8>;
			regulator-always-on;
			regulator-boot-on;
			vin-supply = <0x82>;
			phandle = <0xaf>;

			regulator-state-mem {
				regulator-off-in-suspend;
			};
		};

		pmic@1b {
			compatible = "rockchip,rk808";
			reg = <0x1b>;
			interrupt-parent = <0x83>;
			interrupts = <0x15 0x08>;
			pinctrl-names = "default";
			pinctrl-0 = <0x84>;
			rockchip,system-power-controller;
			wakeup-source;
			#clock-cells = <0x01>;
			clock-output-names = "xin32k\0rk808-clkout2";
			vcc1-supply = <0x82>;
			vcc2-supply = <0x82>;
			vcc3-supply = <0x82>;
			vcc4-supply = <0x82>;
			vcc6-supply = <0x82>;
			vcc7-supply = <0x82>;
			vcc8-supply = <0x1e>;
			vcc9-supply = <0x82>;
			vcc10-supply = <0x82>;
			vcc11-supply = <0x82>;
			vcc12-supply = <0x1e>;
			vddio-supply = <0x7a>;
			phandle = <0x42>;

			regulators {

				DCDC_REG1 {
					regulator-name = "vdd_center";
					regulator-min-microvolt = <0xb71b0>;
					regulator-max-microvolt = <0x149970>;
					regulator-always-on;
					regulator-boot-on;

					regulator-state-mem {
						regulator-off-in-suspend;
					};
				};

				DCDC_REG2 {
					regulator-name = "vdd_cpu_l";
					regulator-min-microvolt = <0xb71b0>;
					regulator-max-microvolt = <0x149970>;
					regulator-always-on;
					regulator-boot-on;
					phandle = <0x0c>;

					regulator-state-mem {
						regulator-off-in-suspend;
					};
				};

				DCDC_REG3 {
					regulator-name = "vcc_ddr";
					regulator-always-on;
					regulator-boot-on;

					regulator-state-mem {
						regulator-on-in-suspend;
					};
				};

				DCDC_REG4 {
					regulator-name = "vcc_1v8";
					regulator-min-microvolt = <0x1b7740>;
					regulator-max-microvolt = <0x1b7740>;
					regulator-always-on;
					regulator-boot-on;
					phandle = <0x7a>;

					regulator-state-mem {
						regulator-on-in-suspend;
						regulator-suspend-microvolt = <0x1b7740>;
					};
				};

				LDO_REG1 {
					regulator-name = "vcc1v8_dvp";
					regulator-min-microvolt = <0x1b7740>;
					regulator-max-microvolt = <0x1b7740>;
					regulator-always-on;
					regulator-boot-on;

					regulator-state-mem {
						regulator-on-in-suspend;
						regulator-suspend-microvolt = <0x1b7740>;
					};
				};

				LDO_REG2 {
					regulator-name = "vcca1v8_hdmi";
					regulator-min-microvolt = <0x1b7740>;
					regulator-max-microvolt = <0x1b7740>;
					regulator-always-on;
					regulator-boot-on;

					regulator-state-mem {
						regulator-on-in-suspend;
						regulator-suspend-microvolt = <0x1b7740>;
					};
				};

				LDO_REG3 {
					regulator-name = "vcca_1v8";
					regulator-min-microvolt = <0x1b7740>;
					regulator-max-microvolt = <0x1b7740>;
					regulator-always-on;
					regulator-boot-on;
					phandle = <0x18>;

					regulator-state-mem {
						regulator-on-in-suspend;
						regulator-suspend-microvolt = <0x1b7740>;
					};
				};

				LDO_REG4 {
					regulator-name = "vcc_sd";
					regulator-min-microvolt = <0x1b7740>;
					regulator-max-microvolt = <0x325aa0>;
					regulator-always-on;
					regulator-boot-on;
					phandle = <0x27>;

					regulator-state-mem {
						regulator-on-in-suspend;
						regulator-suspend-microvolt = <0x325aa0>;
					};
				};

				LDO_REG5 {
					regulator-name = "vcc3v0_sd";
					regulator-min-microvolt = <0x2dc6c0>;
					regulator-max-microvolt = <0x2dc6c0>;
					regulator-always-on;
					regulator-boot-on;

					regulator-state-mem {
						regulator-on-in-suspend;
						regulator-suspend-microvolt = <0x2dc6c0>;
					};
				};

				LDO_REG6 {
					regulator-name = "vcc_1v5";
					regulator-min-microvolt = <0x16e360>;
					regulator-max-microvolt = <0x16e360>;
					regulator-always-on;
					regulator-boot-on;

					regulator-state-mem {
						regulator-on-in-suspend;
						regulator-suspend-microvolt = <0x16e360>;
					};
				};

				LDO_REG7 {
					regulator-name = "vcca0v9_hdmi";
					regulator-min-microvolt = <0xdbba0>;
					regulator-max-microvolt = <0xdbba0>;
					regulator-always-on;
					regulator-boot-on;

					regulator-state-mem {
						regulator-on-in-suspend;
						regulator-suspend-microvolt = <0xdbba0>;
					};
				};

				LDO_REG8 {
					regulator-name = "vcc_3v0";
					regulator-min-microvolt = <0x2dc6c0>;
					regulator-max-microvolt = <0x2dc6c0>;
					regulator-always-on;
					regulator-boot-on;
					phandle = <0x8f>;

					regulator-state-mem {
						regulator-on-in-suspend;
						regulator-suspend-microvolt = <0x2dc6c0>;
					};
				};

				SWITCH_REG1 {
					regulator-name = "vcc3v3_s3";
					regulator-always-on;
					regulator-boot-on;

					regulator-state-mem {
						regulator-on-in-suspend;
					};
				};

				SWITCH_REG2 {
					regulator-name = "vcc3v3_s0";
					regulator-always-on;
					regulator-boot-on;

					regulator-state-mem {
						regulator-on-in-suspend;
					};
				};
			};
		};
	};

	i2c@ff3d0000 {
		compatible = "rockchip,rk3399-i2c";
		reg = <0x00 0xff3d0000 0x00 0x1000>;
		assigned-clocks = <0x7b 0x0a>;
		assigned-clock-rates = <0xbebc200>;
		clocks = <0x7b 0x0a 0x7b 0x1c>;
		clock-names = "i2c\0pclk";
		interrupts = <0x00 0x38 0x04 0x00>;
		pinctrl-names = "default";
		pinctrl-0 = <0x85>;
		#address-cells = <0x01>;
		#size-cells = <0x00>;
		status = "okay";
	};

	i2c@ff3e0000 {
		compatible = "rockchip,rk3399-i2c";
		reg = <0x00 0xff3e0000 0x00 0x1000>;
		assigned-clocks = <0x7b 0x0b>;
		assigned-clock-rates = <0xbebc200>;
		clocks = <0x7b 0x0b 0x7b 0x1d>;
		clock-names = "i2c\0pclk";
		interrupts = <0x00 0x3a 0x04 0x00>;
		pinctrl-names = "default";
		pinctrl-0 = <0x86>;
		#address-cells = <0x01>;
		#size-cells = <0x00>;
		status = "disabled";
	};

	pwm@ff420000 {
		compatible = "rockchip,rk3399-pwm\0rockchip,rk3288-pwm";
		reg = <0x00 0xff420000 0x00 0x10>;
		#pwm-cells = <0x03>;
		pinctrl-names = "default";
		pinctrl-0 = <0x87>;
		clocks = <0x7b 0x1e>;
		clock-names = "pwm";
		status = "disabled";
	};

	pwm@ff420010 {
		compatible = "rockchip,rk3399-pwm\0rockchip,rk3288-pwm";
		reg = <0x00 0xff420010 0x00 0x10>;
		#pwm-cells = <0x03>;
		pinctrl-names = "default";
		pinctrl-0 = <0x88>;
		clocks = <0x7b 0x1e>;
		clock-names = "pwm";
		status = "disabled";
	};

	pwm@ff420020 {
		compatible = "rockchip,rk3399-pwm\0rockchip,rk3288-pwm";
		reg = <0x00 0xff420020 0x00 0x10>;
		#pwm-cells = <0x03>;
		pinctrl-names = "default";
		pinctrl-0 = <0x89>;
		clocks = <0x7b 0x1e>;
		clock-names = "pwm";
		status = "okay";
	};

	pwm@ff420030 {
		compatible = "rockchip,rk3399-pwm\0rockchip,rk3288-pwm";
		reg = <0x00 0xff420030 0x00 0x10>;
		#pwm-cells = <0x03>;
		pinctrl-names = "default";
		pinctrl-0 = <0x8a>;
		clocks = <0x7b 0x1e>;
		clock-names = "pwm";
		status = "okay";
	};

	video-codec@ff650000 {
		compatible = "rockchip,rk3399-vpu";
		reg = <0x00 0xff650000 0x00 0x800>;
		interrupts = <0x00 0x72 0x04 0x00 0x00 0x71 0x04 0x00>;
		interrupt-names = "vepu\0vdpu";
		clocks = <0x08 0xeb 0x08 0x1ea>;
		clock-names = "aclk\0hclk";
		iommus = <0x8b>;
		power-domains = <0x1b 0x1f>;
	};

	iommu@ff650800 {
		compatible = "rockchip,iommu";
		reg = <0x00 0xff650800 0x00 0x40>;
		interrupts = <0x00 0x73 0x04 0x00>;
		interrupt-names = "vpu_mmu";
		clocks = <0x08 0xeb 0x08 0x1ea>;
		clock-names = "aclk\0iface";
		#iommu-cells = <0x00>;
		power-domains = <0x1b 0x1f>;
		phandle = <0x8b>;
	};

	video-codec@ff660000 {
		compatible = "rockchip,rk3399-vdec";
		reg = <0x00 0xff660000 0x00 0x400>;
		interrupts = <0x00 0x74 0x04 0x00>;
		interrupt-names = "vdpu";
		clocks = <0x08 0xed 0x08 0x1ec 0x08 0x9f 0x08 0x9e>;
		clock-names = "axi\0ahb\0cabac\0core";
		iommus = <0x8c>;
		power-domains = <0x1b 0x20>;
	};

	iommu@ff660480 {
		compatible = "rockchip,iommu";
		reg = <0x00 0xff660480 0x00 0x40 0x00 0xff6604c0 0x00 0x40>;
		interrupts = <0x00 0x75 0x04 0x00>;
		interrupt-names = "vdec_mmu";
		clocks = <0x08 0xed 0x08 0x1ec>;
		clock-names = "aclk\0iface";
		power-domains = <0x1b 0x20>;
		#iommu-cells = <0x00>;
		phandle = <0x8c>;
	};

	iommu@ff670800 {
		compatible = "rockchip,iommu";
		reg = <0x00 0xff670800 0x00 0x40>;
		interrupts = <0x00 0x2a 0x04 0x00>;
		interrupt-names = "iep_mmu";
		clocks = <0x08 0xe1 0x08 0x1dd>;
		clock-names = "aclk\0iface";
		#iommu-cells = <0x00>;
		status = "disabled";
	};

	rga@ff680000 {
		compatible = "rockchip,rk3399-rga";
		reg = <0x00 0xff680000 0x00 0x10000>;
		interrupts = <0x00 0x37 0x04 0x00>;
		clocks = <0x08 0xdc 0x08 0x1e5 0x08 0x6d>;
		clock-names = "aclk\0hclk\0sclk";
		resets = <0x08 0x6a 0x08 0x67 0x08 0x69>;
		reset-names = "core\0axi\0ahb";
		power-domains = <0x1b 0x21>;
	};

	efuse@ff690000 {
		compatible = "rockchip,rk3399-efuse";
		reg = <0x00 0xff690000 0x00 0x80>;
		#address-cells = <0x01>;
		#size-cells = <0x01>;
		clocks = <0x08 0x17d>;
		clock-names = "pclk_efuse";

		cpu-id@7 {
			reg = <0x07 0x10>;
		};

		cpu-leakage@17 {
			reg = <0x17 0x01>;
		};

		gpu-leakage@18 {
			reg = <0x18 0x01>;
		};

		center-leakage@19 {
			reg = <0x19 0x01>;
		};

		cpu-leakage@1a {
			reg = <0x1a 0x01>;
		};

		logic-leakage@1b {
			reg = <0x1b 0x01>;
		};

		wafer-info@1c {
			reg = <0x1c 0x01>;
		};
	};

	pmu-clock-controller@ff750000 {
		compatible = "rockchip,rk3399-pmucru";
		reg = <0x00 0xff750000 0x00 0x1000>;
		rockchip,grf = <0x8d>;
		#clock-cells = <0x01>;
		#reset-cells = <0x01>;
		assigned-clocks = <0x7b 0x01>;
		assigned-clock-rates = <0x284af100>;
		phandle = <0x7b>;
	};

	clock-controller@ff760000 {
		compatible = "rockchip,rk3399-cru";
		reg = <0x00 0xff760000 0x00 0x1000>;
		rockchip,grf = <0x1c>;
		#clock-cells = <0x01>;
		#reset-cells = <0x01>;
		assigned-clocks = <0x08 0x05 0x08 0x04 0x08 0x06 0x08 0xc0 0x08 0x1c0 0x08 0x140 0x08 0xc2 0x08 0x1c1 0x08 0x142 0x08 0xc9 0x08 0x1c2 0x08 0x143 0x08 0xe3 0x08 0xde 0x08 0x106 0x08 0x178>;
		assigned-clock-rates = <0x2367b880 0x2faf0800 0x3b9aca00 0x8f0d180 0x47868c0 0x23c3460 0x5f5e100 0x5f5e100 0x2faf080 0x23c34600 0x5f5e100 0x2faf080 0x17d78400 0x17d78400 0xbebc200 0xbebc200>;
		phandle = <0x08>;
	};

	syscon@ff770000 {
		compatible = "rockchip,rk3399-grf\0syscon\0simple-mfd";
		reg = <0x00 0xff770000 0x00 0x10000>;
		#address-cells = <0x01>;
		#size-cells = <0x01>;
		phandle = <0x1c>;

		io-domains {
			compatible = "rockchip,rk3399-io-voltage-domain";
			status = "okay";
			bt656-supply = <0x8e>;
			audio-supply = <0x8e>;
			sdmmc-supply = <0x27>;
			gpio1830-supply = <0x8f>;
		};

		usb2-phy@e450 {
			compatible = "rockchip,rk3399-usb2phy";
			reg = <0xe450 0x10>;
			clocks = <0x08 0x7b>;
			clock-names = "phyclk";
			#clock-cells = <0x00>;
			clock-output-names = "clk_usbphy0_480m";
			status = "okay";
			phandle = <0x2d>;

			host-port {
				#phy-cells = <0x00>;
				interrupts = <0x00 0x1b 0x04 0x00>;
				interrupt-names = "linestate";
				status = "okay";
				phy-supply = <0x90>;
				phandle = <0x2e>;
			};

			otg-port {
				#phy-cells = <0x00>;
				interrupts = <0x00 0x67 0x04 0x00 0x00 0x68 0x04 0x00 0x00 0x6a 0x04 0x00>;
				interrupt-names = "otg-bvalid\0otg-id\0linestate";
				status = "okay";
				phandle = <0x31>;
			};
		};

		usb2-phy@e460 {
			compatible = "rockchip,rk3399-usb2phy";
			reg = <0xe460 0x10>;
			clocks = <0x08 0x7c>;
			clock-names = "phyclk";
			#clock-cells = <0x00>;
			clock-output-names = "clk_usbphy1_480m";
			status = "okay";
			phandle = <0x2f>;

			host-port {
				#phy-cells = <0x00>;
				interrupts = <0x00 0x1f 0x04 0x00>;
				interrupt-names = "linestate";
				status = "okay";
				phy-supply = <0x90>;
				phandle = <0x30>;
			};

			otg-port {
				#phy-cells = <0x00>;
				interrupts = <0x00 0x6c 0x04 0x00 0x00 0x6d 0x04 0x00 0x00 0x6f 0x04 0x00>;
				interrupt-names = "otg-bvalid\0otg-id\0linestate";
				status = "okay";
				phandle = <0x33>;
			};
		};

		phy@f780 {
			compatible = "rockchip,rk3399-emmc-phy";
			reg = <0xf780 0x24>;
			clocks = <0x91>;
			clock-names = "emmcclk";
			#phy-cells = <0x00>;
			status = "okay";
			phandle = <0x2c>;
		};

		pcie-phy {
			compatible = "rockchip,rk3399-pcie-phy";
			clocks = <0x08 0x8a>;
			clock-names = "refclk";
			#phy-cells = <0x01>;
			resets = <0x08 0x87>;
			drive-impedance-ohm = <0x32>;
			reset-names = "phy";
			status = "okay";
			phandle = <0x15>;
		};
	};

	phy@ff7c0000 {
		compatible = "rockchip,rk3399-typec-phy";
		reg = <0x00 0xff7c0000 0x00 0x40000>;
		clocks = <0x08 0x7e 0x08 0x7d>;
		clock-names = "tcpdcore\0tcpdphy-ref";
		assigned-clocks = <0x08 0x7e>;
		assigned-clock-rates = <0x2faf080>;
		power-domains = <0x1b 0x08>;
		resets = <0x08 0x95 0x08 0x94 0x08 0x14c>;
		reset-names = "uphy\0uphy-pipe\0uphy-tcphy";
		rockchip,grf = <0x1c>;
		status = "okay";

		dp-port {
			#phy-cells = <0x00>;
			phandle = <0x35>;
		};

		usb3-port {
			#phy-cells = <0x00>;
			phandle = <0x32>;
		};
	};

	phy@ff800000 {
		compatible = "rockchip,rk3399-typec-phy";
		reg = <0x00 0xff800000 0x00 0x40000>;
		clocks = <0x08 0x80 0x08 0x7f>;
		clock-names = "tcpdcore\0tcpdphy-ref";
		assigned-clocks = <0x08 0x80>;
		assigned-clock-rates = <0x2faf080>;
		power-domains = <0x1b 0x09>;
		resets = <0x08 0x9d 0x08 0x9c 0x08 0x14d>;
		reset-names = "uphy\0uphy-pipe\0uphy-tcphy";
		rockchip,grf = <0x1c>;
		status = "okay";

		dp-port {
			#phy-cells = <0x00>;
			phandle = <0x36>;
		};

		usb3-port {
			#phy-cells = <0x00>;
			phandle = <0x34>;
		};
	};

	watchdog@ff848000 {
		compatible = "snps,dw-wdt";
		reg = <0x00 0xff848000 0x00 0x100>;
		clocks = <0x08 0x17c>;
		interrupts = <0x00 0x78 0x04 0x00>;
	};

	rktimer@ff850000 {
		compatible = "rockchip,rk3399-timer";
		reg = <0x00 0xff850000 0x00 0x1000>;
		interrupts = <0x00 0x51 0x04 0x00>;
		clocks = <0x08 0x168 0x08 0x5a>;
		clock-names = "pclk\0timer";
	};

	spdif@ff870000 {
		compatible = "rockchip,rk3399-spdif";
		reg = <0x00 0xff870000 0x00 0x1000>;
		interrupts = <0x00 0x42 0x04 0x00>;
		dmas = <0x5a 0x07>;
		dma-names = "tx";
		clock-names = "mclk\0hclk";
		clocks = <0x08 0x55 0x08 0x1d7>;
		pinctrl-names = "default";
		pinctrl-0 = <0x92>;
		power-domains = <0x1b 0x1c>;
		#sound-dai-cells = <0x00>;
		status = "disabled";
	};

	i2s@ff880000 {
		compatible = "rockchip,rk3399-i2s\0rockchip,rk3066-i2s";
		reg = <0x00 0xff880000 0x00 0x1000>;
		rockchip,grf = <0x1c>;
		interrupts = <0x00 0x27 0x04 0x00>;
		dmas = <0x5a 0x00 0x5a 0x01>;
		dma-names = "tx\0rx";
		clock-names = "i2s_clk\0i2s_hclk";
		clocks = <0x08 0x56 0x08 0x1d4>;
		pinctrl-names = "default";
		pinctrl-0 = <0x93>;
		power-domains = <0x1b 0x1c>;
		#sound-dai-cells = <0x00>;
		status = "disabled";
	};

	i2s@ff890000 {
		compatible = "rockchip,rk3399-i2s\0rockchip,rk3066-i2s";
		reg = <0x00 0xff890000 0x00 0x1000>;
		interrupts = <0x00 0x28 0x04 0x00>;
		dmas = <0x5a 0x02 0x5a 0x03>;
		dma-names = "tx\0rx";
		clock-names = "i2s_clk\0i2s_hclk";
		clocks = <0x08 0x57 0x08 0x1d5>;
		pinctrl-names = "default";
		pinctrl-0 = <0x94>;
		power-domains = <0x1b 0x1c>;
		#sound-dai-cells = <0x00>;
		status = "disabled";
	};

	i2s@ff8a0000 {
		compatible = "rockchip,rk3399-i2s\0rockchip,rk3066-i2s";
		reg = <0x00 0xff8a0000 0x00 0x1000>;
		interrupts = <0x00 0x29 0x04 0x00>;
		dmas = <0x5a 0x04 0x5a 0x05>;
		dma-names = "tx\0rx";
		clock-names = "i2s_clk\0i2s_hclk";
		clocks = <0x08 0x58 0x08 0x1d6>;
		power-domains = <0x1b 0x1c>;
		#sound-dai-cells = <0x00>;
		status = "okay";
		phandle = <0xa1>;
	};

	vop@ff8f0000 {
		compatible = "rockchip,rk3399-vop-lit";
		reg = <0x00 0xff8f0000 0x00 0x3efc>;
		interrupts = <0x00 0x77 0x04 0x00>;
		assigned-clocks = <0x08 0xdb 0x08 0x1db>;
		assigned-clock-rates = <0x17d78400 0xbebc200>;
		clocks = <0x08 0xdb 0x08 0xb5 0x08 0x1db>;
		clock-names = "aclk_vop\0dclk_vop\0hclk_vop";
		iommus = <0x95>;
		power-domains = <0x1b 0x12>;
		resets = <0x08 0x113 0x08 0x117 0x08 0x119>;
		reset-names = "axi\0ahb\0dclk";
		status = "disabled";

		port {
			#address-cells = <0x01>;
			#size-cells = <0x00>;
			phandle = <0x0f>;

			endpoint@0 {
				reg = <0x00>;
				remote-endpoint = <0x96>;
				phandle = <0xa8>;
			};

			endpoint@1 {
				reg = <0x01>;
				remote-endpoint = <0x97>;
				phandle = <0xad>;
			};

			endpoint@2 {
				reg = <0x02>;
				remote-endpoint = <0x98>;
				phandle = <0xa6>;
			};

			endpoint@3 {
				reg = <0x03>;
				remote-endpoint = <0x99>;
				phandle = <0xaa>;
			};

			endpoint@4 {
				reg = <0x04>;
				remote-endpoint = <0x9a>;
				phandle = <0x38>;
			};
		};
	};

	iommu@ff8f3f00 {
		compatible = "rockchip,iommu";
		reg = <0x00 0xff8f3f00 0x00 0x100>;
		interrupts = <0x00 0x77 0x04 0x00>;
		interrupt-names = "vopl_mmu";
		clocks = <0x08 0xdb 0x08 0x1db>;
		clock-names = "aclk\0iface";
		power-domains = <0x1b 0x12>;
		#iommu-cells = <0x00>;
		status = "disabled";
		phandle = <0x95>;
	};

	vop@ff900000 {
		compatible = "rockchip,rk3399-vop-big";
		reg = <0x00 0xff900000 0x00 0x3efc>;
		interrupts = <0x00 0x76 0x04 0x00>;
		assigned-clocks = <0x08 0xd9 0x08 0x1d9>;
		assigned-clock-rates = <0x17d78400 0xbebc200>;
		clocks = <0x08 0xd9 0x08 0xb4 0x08 0x1d9>;
		clock-names = "aclk_vop\0dclk_vop\0hclk_vop";
		iommus = <0x9b>;
		power-domains = <0x1b 0x11>;
		resets = <0x08 0x112 0x08 0x116 0x08 0x118>;
		reset-names = "axi\0ahb\0dclk";
		status = "okay";

		port {
			#address-cells = <0x01>;
			#size-cells = <0x00>;
			phandle = <0x10>;

			endpoint@0 {
				reg = <0x00>;
				remote-endpoint = <0x9c>;
				phandle = <0xac>;
			};

			endpoint@1 {
				reg = <0x01>;
				remote-endpoint = <0x9d>;
				phandle = <0xa7>;
			};

			endpoint@2 {
				reg = <0x02>;
				remote-endpoint = <0x9e>;
				phandle = <0xa5>;
			};

			endpoint@3 {
				reg = <0x03>;
				remote-endpoint = <0x9f>;
				phandle = <0xa9>;
			};

			endpoint@4 {
				reg = <0x04>;
				remote-endpoint = <0xa0>;
				phandle = <0x37>;
			};
		};
	};

	iommu@ff903f00 {
		compatible = "rockchip,iommu";
		reg = <0x00 0xff903f00 0x00 0x100>;
		interrupts = <0x00 0x76 0x04 0x00>;
		interrupt-names = "vopb_mmu";
		clocks = <0x08 0xd9 0x08 0x1d9>;
		clock-names = "aclk\0iface";
		power-domains = <0x1b 0x11>;
		#iommu-cells = <0x00>;
		status = "okay";
		phandle = <0x9b>;
	};

	iommu@ff914000 {
		compatible = "rockchip,iommu";
		reg = <0x00 0xff914000 0x00 0x100 0x00 0xff915000 0x00 0x100>;
		interrupts = <0x00 0x2b 0x04 0x00>;
		interrupt-names = "isp0_mmu";
		clocks = <0x08 0xe9 0x08 0x1e3>;
		clock-names = "aclk\0iface";
		#iommu-cells = <0x00>;
		power-domains = <0x1b 0x13>;
		rockchip,disable-mmu-reset;
	};

	iommu@ff924000 {
		compatible = "rockchip,iommu";
		reg = <0x00 0xff924000 0x00 0x100 0x00 0xff925000 0x00 0x100>;
		interrupts = <0x00 0x2c 0x04 0x00>;
		interrupt-names = "isp1_mmu";
		clocks = <0x08 0xea 0x08 0x1e4>;
		clock-names = "aclk\0iface";
		#iommu-cells = <0x00>;
		power-domains = <0x1b 0x14>;
		rockchip,disable-mmu-reset;
	};

	hdmi-sound {
		compatible = "simple-audio-card";
		simple-audio-card,format = "i2s";
		simple-audio-card,mclk-fs = <0x100>;
		simple-audio-card,name = "hdmi-sound";
		status = "okay";

		simple-audio-card,cpu {
			sound-dai = <0xa1>;
		};

		simple-audio-card,codec {
			sound-dai = <0xa2>;
		};
	};

	hdmi@ff940000 {
		compatible = "rockchip,rk3399-dw-hdmi";
		reg = <0x00 0xff940000 0x00 0x20000>;
		interrupts = <0x00 0x17 0x04 0x00>;
		clocks = <0x08 0x174 0x08 0x71 0x08 0x07 0x08 0x16f 0x08 0x70>;
		clock-names = "iahb\0isfr\0vpll\0grf\0cec";
		power-domains = <0x1b 0x15>;
		reg-io-width = <0x04>;
		rockchip,grf = <0x1c>;
		#sound-dai-cells = <0x00>;
		status = "okay";
		ddc-i2c-bus = <0xa3>;
		pinctrl-names = "default";
		pinctrl-0 = <0xa4>;
		phandle = <0xa2>;

		ports {

			port {
				#address-cells = <0x01>;
				#size-cells = <0x00>;

				endpoint@0 {
					reg = <0x00>;
					remote-endpoint = <0xa5>;
					phandle = <0x9e>;
				};

				endpoint@1 {
					reg = <0x01>;
					remote-endpoint = <0xa6>;
					phandle = <0x98>;
				};
			};
		};
	};

	mipi@ff960000 {
		compatible = "rockchip,rk3399-mipi-dsi\0snps,dw-mipi-dsi";
		reg = <0x00 0xff960000 0x00 0x8000>;
		interrupts = <0x00 0x2d 0x04 0x00>;
		clocks = <0x08 0xa2 0x08 0x170 0x08 0xa3 0x08 0x16f>;
		clock-names = "ref\0pclk\0phy_cfg\0grf";
		power-domains = <0x1b 0x0f>;
		resets = <0x08 0xfb>;
		reset-names = "apb";
		rockchip,grf = <0x1c>;
		#address-cells = <0x01>;
		#size-cells = <0x00>;
		status = "disabled";

		ports {
			#address-cells = <0x01>;
			#size-cells = <0x00>;

			port@0 {
				reg = <0x00>;
				#address-cells = <0x01>;
				#size-cells = <0x00>;

				endpoint@0 {
					reg = <0x00>;
					remote-endpoint = <0xa7>;
					phandle = <0x9d>;
				};

				endpoint@1 {
					reg = <0x01>;
					remote-endpoint = <0xa8>;
					phandle = <0x96>;
				};
			};
		};
	};

	mipi@ff968000 {
		compatible = "rockchip,rk3399-mipi-dsi\0snps,dw-mipi-dsi";
		reg = <0x00 0xff968000 0x00 0x8000>;
		interrupts = <0x00 0x2e 0x04 0x00>;
		clocks = <0x08 0xa2 0x08 0x171 0x08 0xa4 0x08 0x16f>;
		clock-names = "ref\0pclk\0phy_cfg\0grf";
		power-domains = <0x1b 0x0f>;
		resets = <0x08 0xfc>;
		reset-names = "apb";
		rockchip,grf = <0x1c>;
		#address-cells = <0x01>;
		#size-cells = <0x00>;
		status = "disabled";

		ports {
			#address-cells = <0x01>;
			#size-cells = <0x00>;

			port@0 {
				reg = <0x00>;
				#address-cells = <0x01>;
				#size-cells = <0x00>;

				endpoint@0 {
					reg = <0x00>;
					remote-endpoint = <0xa9>;
					phandle = <0x9f>;
				};

				endpoint@1 {
					reg = <0x01>;
					remote-endpoint = <0xaa>;
					phandle = <0x99>;
				};
			};
		};
	};

	edp@ff970000 {
		compatible = "rockchip,rk3399-edp";
		reg = <0x00 0xff970000 0x00 0x8000>;
		interrupts = <0x00 0x0a 0x04 0x00>;
		clocks = <0x08 0x16a 0x08 0x16c 0x08 0x16f>;
		clock-names = "dp\0pclk\0grf";
		pinctrl-names = "default";
		pinctrl-0 = <0xab>;
		power-domains = <0x1b 0x19>;
		resets = <0x08 0x11d>;
		reset-names = "dp";
		rockchip,grf = <0x1c>;
		status = "disabled";

		ports {
			#address-cells = <0x01>;
			#size-cells = <0x00>;

			port@0 {
				reg = <0x00>;
				#address-cells = <0x01>;
				#size-cells = <0x00>;

				endpoint@0 {
					reg = <0x00>;
					remote-endpoint = <0xac>;
					phandle = <0x9c>;
				};

				endpoint@1 {
					reg = <0x01>;
					remote-endpoint = <0xad>;
					phandle = <0x97>;
				};
			};
		};
	};

	gpu@ff9a0000 {
		compatible = "rockchip,rk3399-mali\0arm,mali-t860";
		reg = <0x00 0xff9a0000 0x00 0x10000>;
		interrupts = <0x00 0x14 0x04 0x00 0x00 0x15 0x04 0x00 0x00 0x13 0x04 0x00>;
		interrupt-names = "job\0mmu\0gpu";
		clocks = <0x08 0xd0>;
		#cooling-cells = <0x02>;
		power-domains = <0x1b 0x23>;
		status = "okay";
		operating-points-v2 = <0xae>;
		mali-supply = <0xaf>;
		phandle = <0x62>;
	};

	pinctrl {
		compatible = "rockchip,rk3399-pinctrl";
		rockchip,grf = <0x1c>;
		rockchip,pmu = <0x8d>;
		#address-cells = <0x02>;
		#size-cells = <0x02>;
		ranges;

		gpio0@ff720000 {
			compatible = "rockchip,gpio-bank";
			reg = <0x00 0xff720000 0x00 0x100>;
			clocks = <0x7b 0x17>;
			interrupts = <0x00 0x0e 0x04 0x00>;
			gpio-controller;
			#gpio-cells = <0x02>;
			interrupt-controller;
			#interrupt-cells = <0x02>;
			phandle = <0x25>;
		};

		gpio1@ff730000 {
			compatible = "rockchip,gpio-bank";
			reg = <0x00 0xff730000 0x00 0x100>;
			clocks = <0x7b 0x18>;
			interrupts = <0x00 0x0f 0x04 0x00>;
			gpio-controller;
			#gpio-cells = <0x02>;
			interrupt-controller;
			#interrupt-cells = <0x02>;
			phandle = <0x83>;
		};

		gpio2@ff780000 {
			compatible = "rockchip,gpio-bank";
			reg = <0x00 0xff780000 0x00 0x100>;
			clocks = <0x08 0x150>;
			interrupts = <0x00 0x10 0x04 0x00>;
			gpio-controller;
			#gpio-cells = <0x02>;
			interrupt-controller;
			#interrupt-cells = <0x02>;
			phandle = <0x1a>;
		};

		gpio3@ff788000 {
			compatible = "rockchip,gpio-bank";
			reg = <0x00 0xff788000 0x00 0x100>;
			clocks = <0x08 0x151>;
			interrupts = <0x00 0x11 0x04 0x00>;
			gpio-controller;
			#gpio-cells = <0x02>;
			interrupt-controller;
			#interrupt-cells = <0x02>;
			phandle = <0x20>;
		};

		gpio4@ff790000 {
			compatible = "rockchip,gpio-bank";
			reg = <0x00 0xff790000 0x00 0x100>;
			clocks = <0x08 0x152>;
			interrupts = <0x00 0x12 0x04 0x00>;
			gpio-controller;
			#gpio-cells = <0x02>;
			interrupt-controller;
			#interrupt-cells = <0x02>;
			phandle = <0xbe>;
		};

		pcfg-pull-up {
			bias-pull-up;
			phandle = <0xb4>;
		};

		pcfg-pull-down {
			bias-pull-down;
			phandle = <0xb9>;
		};

		pcfg-pull-none {
			bias-disable;
			phandle = <0xb0>;
		};

		pcfg-pull-none-12ma {
			bias-disable;
			drive-strength = <0x0c>;
			phandle = <0xb3>;
		};

		pcfg-pull-none-13ma {
			bias-disable;
			drive-strength = <0x0d>;
			phandle = <0xb1>;
		};

		pcfg-pull-none-18ma {
			bias-disable;
			drive-strength = <0x12>;
			phandle = <0xb8>;
		};

		pcfg-pull-none-20ma {
			bias-disable;
			drive-strength = <0x14>;
			phandle = <0xb6>;
		};

		pcfg-pull-up-2ma {
			bias-pull-up;
			drive-strength = <0x02>;
		};

		pcfg-pull-up-8ma {
			bias-pull-up;
			drive-strength = <0x08>;
			phandle = <0xb7>;
		};

		pcfg-pull-up-18ma {
			bias-pull-up;
			drive-strength = <0x12>;
		};

		pcfg-pull-up-20ma {
			bias-pull-up;
			drive-strength = <0x14>;
			phandle = <0xb5>;
		};

		pcfg-pull-down-4ma {
			bias-pull-down;
			drive-strength = <0x04>;
		};

		pcfg-pull-down-8ma {
			bias-pull-down;
			drive-strength = <0x08>;
		};

		pcfg-pull-down-12ma {
			bias-pull-down;
			drive-strength = <0x0c>;
		};

		pcfg-pull-down-18ma {
			bias-pull-down;
			drive-strength = <0x12>;
		};

		pcfg-pull-down-20ma {
			bias-pull-down;
			drive-strength = <0x14>;
		};

		pcfg-output-high {
			output-high;
		};

		pcfg-output-low {
			output-low;
			phandle = <0xb2>;
		};

		clock {

			clk-32k {
				rockchip,pins = <0x00 0x00 0x02 0xb0>;
			};
		};

		edp {

			edp-hpd {
				rockchip,pins = <0x04 0x17 0x02 0xb0>;
				phandle = <0xab>;
			};
		};

		gmac {

			rgmii-pins {
				rockchip,pins = <0x03 0x11 0x01 0xb1 0x03 0x0e 0x01 0xb0 0x03 0x0d 0x01 0xb0 0x03 0x0c 0x01 0xb1 0x03 0x0b 0x01 0xb0 0x03 0x09 0x01 0xb0 0x03 0x08 0x01 0xb0 0x03 0x07 0x01 0xb0 0x03 0x06 0x01 0xb0 0x03 0x05 0x01 0xb1 0x03 0x04 0x01 0xb1 0x03 0x03 0x01 0xb0 0x03 0x02 0x01 0xb0 0x03 0x01 0x01 0xb1 0x03 0x00 0x01 0xb1>;
				phandle = <0x1f>;
			};

			rmii-pins {
				rockchip,pins = <0x03 0x0d 0x01 0xb0 0x03 0x0c 0x01 0xb1 0x03 0x0b 0x01 0xb0 0x03 0x0a 0x01 0xb0 0x03 0x09 0x01 0xb0 0x03 0x08 0x01 0xb0 0x03 0x07 0x01 0xb0 0x03 0x06 0x01 0xb0 0x03 0x05 0x01 0xb1 0x03 0x04 0x01 0xb1>;
			};

			rgmii-sleep-pins {
				rockchip,pins = <0x01 0x0a 0x00 0xb2>;
			};
		};

		i2c0 {

			i2c0-xfer {
				rockchip,pins = <0x01 0x0f 0x02 0xb0 0x01 0x10 0x02 0xb0>;
				phandle = <0x81>;
			};
		};

		i2c1 {

			i2c1-xfer {
				rockchip,pins = <0x04 0x02 0x01 0xb0 0x04 0x01 0x01 0xb0>;
				phandle = <0x39>;
			};
		};

		i2c2 {

			i2c2-xfer {
				rockchip,pins = <0x02 0x01 0x02 0xb3 0x02 0x00 0x02 0xb3>;
				phandle = <0x3a>;
			};
		};

		i2c3 {

			i2c3-xfer {
				rockchip,pins = <0x04 0x11 0x01 0xb0 0x04 0x10 0x01 0xb0>;
				phandle = <0x3b>;
			};
		};

		i2c4 {

			i2c4-xfer {
				rockchip,pins = <0x01 0x0c 0x01 0xb0 0x01 0x0b 0x01 0xb0>;
				phandle = <0x85>;
			};
		};

		i2c5 {

			i2c5-xfer {
				rockchip,pins = <0x03 0x0b 0x02 0xb0 0x03 0x0a 0x02 0xb0>;
				phandle = <0x3c>;
			};
		};

		i2c6 {

			i2c6-xfer {
				rockchip,pins = <0x02 0x0a 0x02 0xb0 0x02 0x09 0x02 0xb0>;
				phandle = <0x3d>;
			};
		};

		i2c7 {

			i2c7-xfer {
				rockchip,pins = <0x02 0x08 0x02 0xb0 0x02 0x07 0x02 0xb0>;
				phandle = <0x3e>;
			};
		};

		i2c8 {

			i2c8-xfer {
				rockchip,pins = <0x01 0x15 0x01 0xb0 0x01 0x14 0x01 0xb0>;
				phandle = <0x86>;
			};
		};

		i2s0 {

			i2s0-2ch-bus {
				rockchip,pins = <0x03 0x18 0x01 0xb0 0x03 0x19 0x01 0xb0 0x03 0x1a 0x01 0xb0 0x03 0x1b 0x01 0xb0 0x03 0x1f 0x01 0xb0 0x04 0x00 0x01 0xb0>;
			};

			i2s0-8ch-bus {
				rockchip,pins = <0x03 0x18 0x01 0xb0 0x03 0x19 0x01 0xb0 0x03 0x1a 0x01 0xb0 0x03 0x1b 0x01 0xb0 0x03 0x1c 0x01 0xb0 0x03 0x1d 0x01 0xb0 0x03 0x1e 0x01 0xb0 0x03 0x1f 0x01 0xb0 0x04 0x00 0x01 0xb0>;
				phandle = <0x93>;
			};
		};

		i2s1 {

			i2s1-2ch-bus {
				rockchip,pins = <0x04 0x03 0x01 0xb0 0x04 0x04 0x01 0xb0 0x04 0x05 0x01 0xb0 0x04 0x06 0x01 0xb0 0x04 0x07 0x01 0xb0>;
				phandle = <0x94>;
			};
		};

		sdio0 {

			sdio0-bus1 {
				rockchip,pins = <0x02 0x14 0x01 0xb4>;
			};

			sdio0-bus4 {
				rockchip,pins = <0x02 0x14 0x01 0xb5 0x02 0x15 0x01 0xb5 0x02 0x16 0x01 0xb5 0x02 0x17 0x01 0xb5>;
				phandle = <0x22>;
			};

			sdio0-cmd {
				rockchip,pins = <0x02 0x18 0x01 0xb5>;
				phandle = <0x23>;
			};

			sdio0-clk {
				rockchip,pins = <0x02 0x19 0x01 0xb6>;
				phandle = <0x24>;
			};

			sdio0-cd {
				rockchip,pins = <0x02 0x1a 0x01 0xb4>;
			};

			sdio0-pwr {
				rockchip,pins = <0x02 0x1b 0x01 0xb4>;
			};

			sdio0-bkpwr {
				rockchip,pins = <0x02 0x1c 0x01 0xb4>;
			};

			sdio0-wp {
				rockchip,pins = <0x00 0x03 0x01 0xb4>;
			};

			sdio0-int {
				rockchip,pins = <0x00 0x04 0x01 0xb4>;
			};
		};

		sdmmc {

			sdmmc-bus1 {
				rockchip,pins = <0x04 0x08 0x01 0xb7>;
			};

			sdmmc-bus4 {
				rockchip,pins = <0x04 0x08 0x01 0xb7 0x04 0x09 0x01 0xb7 0x04 0x0a 0x01 0xb7 0x04 0x0b 0x01 0xb7>;
				phandle = <0x2b>;
			};

			sdmmc-clk {
				rockchip,pins = <0x04 0x0c 0x01 0xb8>;
				phandle = <0x28>;
			};

			sdmmc-cmd {
				rockchip,pins = <0x04 0x0d 0x01 0xb7>;
				phandle = <0x29>;
			};

			sdmmc-cd {
				rockchip,pins = <0x00 0x07 0x01 0xb4>;
				phandle = <0x2a>;
			};

			sdmmc-wp {
				rockchip,pins = <0x00 0x08 0x01 0xb4>;
			};
		};

		sleep {

			ap-pwroff {
				rockchip,pins = <0x01 0x05 0x01 0xb0>;
			};

			ddrio-pwroff {
				rockchip,pins = <0x00 0x01 0x01 0xb0>;
			};
		};

		spdif {

			spdif-bus {
				rockchip,pins = <0x04 0x15 0x01 0xb0>;
				phandle = <0x92>;
			};

			spdif-bus-1 {
				rockchip,pins = <0x03 0x10 0x03 0xb0>;
			};
		};

		spi0 {

			spi0-clk {
				rockchip,pins = <0x03 0x06 0x02 0xb4>;
				phandle = <0x4a>;
			};

			spi0-cs0 {
				rockchip,pins = <0x03 0x07 0x02 0xb4>;
				phandle = <0x4d>;
			};

			spi0-cs1 {
				rockchip,pins = <0x03 0x08 0x02 0xb4>;
			};

			spi0-tx {
				rockchip,pins = <0x03 0x05 0x02 0xb4>;
				phandle = <0x4b>;
			};

			spi0-rx {
				rockchip,pins = <0x03 0x04 0x02 0xb4>;
				phandle = <0x4c>;
			};
		};

		spi1 {

			spi1-clk {
				rockchip,pins = <0x01 0x09 0x02 0xb4>;
				phandle = <0x4e>;
			};

			spi1-cs0 {
				rockchip,pins = <0x01 0x0a 0x02 0xb4>;
				phandle = <0x51>;
			};

			spi1-rx {
				rockchip,pins = <0x01 0x07 0x02 0xb4>;
				phandle = <0x50>;
			};

			spi1-tx {
				rockchip,pins = <0x01 0x08 0x02 0xb4>;
				phandle = <0x4f>;
			};
		};

		spi2 {

			spi2-clk {
				rockchip,pins = <0x02 0x0b 0x01 0xb4>;
				phandle = <0x52>;
			};

			spi2-cs0 {
				rockchip,pins = <0x02 0x0c 0x01 0xb4>;
				phandle = <0x55>;
			};

			spi2-rx {
				rockchip,pins = <0x02 0x09 0x01 0xb4>;
				phandle = <0x54>;
			};

			spi2-tx {
				rockchip,pins = <0x02 0x0a 0x01 0xb4>;
				phandle = <0x53>;
			};
		};

		spi3 {

			spi3-clk {
				rockchip,pins = <0x01 0x11 0x01 0xb4>;
				phandle = <0x7c>;
			};

			spi3-cs0 {
				rockchip,pins = <0x01 0x12 0x01 0xb4>;
				phandle = <0x7f>;
			};

			spi3-rx {
				rockchip,pins = <0x01 0x0f 0x01 0xb4>;
				phandle = <0x7e>;
			};

			spi3-tx {
				rockchip,pins = <0x01 0x10 0x01 0xb4>;
				phandle = <0x7d>;
			};
		};

		spi4 {

			spi4-clk {
				rockchip,pins = <0x03 0x02 0x02 0xb4>;
				phandle = <0x56>;
			};

			spi4-cs0 {
				rockchip,pins = <0x03 0x03 0x02 0xb4>;
				phandle = <0x59>;
			};

			spi4-rx {
				rockchip,pins = <0x03 0x00 0x02 0xb4>;
				phandle = <0x58>;
			};

			spi4-tx {
				rockchip,pins = <0x03 0x01 0x02 0xb4>;
				phandle = <0x57>;
			};
		};

		spi5 {

			spi5-clk {
				rockchip,pins = <0x02 0x16 0x02 0xb4>;
				phandle = <0x5b>;
			};

			spi5-cs0 {
				rockchip,pins = <0x02 0x17 0x02 0xb4>;
				phandle = <0x5e>;
			};

			spi5-rx {
				rockchip,pins = <0x02 0x14 0x02 0xb4>;
				phandle = <0x5d>;
			};

			spi5-tx {
				rockchip,pins = <0x02 0x15 0x02 0xb4>;
				phandle = <0x5c>;
			};
		};

		testclk {

			test-clkout0 {
				rockchip,pins = <0x00 0x00 0x01 0xb0>;
			};

			test-clkout1 {
				rockchip,pins = <0x02 0x19 0x02 0xb0>;
			};

			test-clkout2 {
				rockchip,pins = <0x00 0x08 0x03 0xb0>;
			};
		};

		tsadc {

			otp-gpio {
				rockchip,pins = <0x01 0x06 0x00 0xb0>;
				phandle = <0x63>;
			};

			otp-out {
				rockchip,pins = <0x01 0x06 0x01 0xb0>;
				phandle = <0x64>;
			};
		};

		uart0 {

			uart0-xfer {
				rockchip,pins = <0x02 0x10 0x01 0xb4 0x02 0x11 0x01 0xb0>;
				phandle = <0x3f>;
			};

			uart0-cts {
				rockchip,pins = <0x02 0x12 0x01 0xb0>;
				phandle = <0x40>;
			};

			uart0-rts {
				rockchip,pins = <0x02 0x13 0x01 0xb0>;
				phandle = <0x41>;
			};
		};

		uart1 {

			uart1-xfer {
				rockchip,pins = <0x03 0x0c 0x02 0xb4 0x03 0x0d 0x02 0xb0>;
				phandle = <0x46>;
			};
		};

		uart2a {

			uart2a-xfer {
				rockchip,pins = <0x04 0x08 0x02 0xb4 0x04 0x09 0x02 0xb0>;
			};
		};

		uart2b {

			uart2b-xfer {
				rockchip,pins = <0x04 0x10 0x02 0xb4 0x04 0x11 0x02 0xb0>;
			};
		};

		uart2c {

			uart2c-xfer {
				rockchip,pins = <0x04 0x13 0x01 0xb4 0x04 0x14 0x01 0xb0>;
				phandle = <0x47>;
			};
		};

		uart3 {

			uart3-xfer {
				rockchip,pins = <0x03 0x0e 0x02 0xb4 0x03 0x0f 0x02 0xb0>;
				phandle = <0x48>;
			};

			uart3-cts {
				rockchip,pins = <0x03 0x10 0x02 0xb0>;
			};

			uart3-rts {
				rockchip,pins = <0x03 0x11 0x02 0xb0>;
			};
		};

		uart4 {

			uart4-xfer {
				rockchip,pins = <0x01 0x07 0x01 0xb4 0x01 0x08 0x01 0xb0>;
				phandle = <0x80>;
			};
		};

		uarthdcp {

			uarthdcp-xfer {
				rockchip,pins = <0x04 0x15 0x02 0xb4 0x04 0x16 0x02 0xb0>;
			};
		};

		pwm0 {

			pwm0-pin {
				rockchip,pins = <0x04 0x12 0x01 0xb0>;
				phandle = <0x87>;
			};

			pwm0-pin-pull-down {
				rockchip,pins = <0x04 0x12 0x01 0xb9>;
			};

			vop0-pwm-pin {
				rockchip,pins = <0x04 0x12 0x02 0xb0>;
			};

			vop1-pwm-pin {
				rockchip,pins = <0x04 0x12 0x03 0xb0>;
			};
		};

		pwm1 {

			pwm1-pin {
				rockchip,pins = <0x04 0x16 0x01 0xb0>;
				phandle = <0x88>;
			};

			pwm1-pin-pull-down {
				rockchip,pins = <0x04 0x16 0x01 0xb9>;
			};
		};

		pwm2 {

			pwm2-pin {
				rockchip,pins = <0x01 0x13 0x01 0xb0>;
				phandle = <0x89>;
			};

			pwm2-pin-pull-down {
				rockchip,pins = <0x01 0x13 0x01 0xb9>;
			};
		};

		pwm3a {

			pwm3a-pin {
				rockchip,pins = <0x00 0x06 0x01 0xb0>;
				phandle = <0x8a>;
			};
		};

		pwm3b {

			pwm3b-pin {
				rockchip,pins = <0x01 0x0e 0x01 0xb0>;
			};
		};

		hdmi {

			hdmi-i2c-xfer {
				rockchip,pins = <0x04 0x11 0x03 0xb0 0x04 0x10 0x03 0xb0>;
			};

			hdmi-cec {
				rockchip,pins = <0x04 0x17 0x01 0xb0>;
				phandle = <0xa4>;
			};
		};

		pcie {

			pci-clkreqn-cpm {
				rockchip,pins = <0x02 0x1a 0x00 0xb0>;
				phandle = <0x16>;
			};

			pci-clkreqnb-cpm {
				rockchip,pins = <0x04 0x18 0x00 0xb0>;
			};

			pcie-drv {
				rockchip,pins = <0x02 0x05 0x00 0xb0>;
				phandle = <0xbc>;
			};
		};

		bt {

			bt-enable-h {
				rockchip,pins = <0x00 0x09 0x00 0xb0>;
				phandle = <0x45>;
			};

			bt-host-wake-l {
				rockchip,pins = <0x00 0x04 0x00 0xb0>;
				phandle = <0x43>;
			};

			bt-wake-l {
				rockchip,pins = <0x02 0x1b 0x00 0xb0>;
				phandle = <0x44>;
			};
		};

		pmic {

			pmic-int-l {
				rockchip,pins = <0x01 0x15 0x00 0xb4>;
				phandle = <0x84>;
			};

			vsel1-gpio {
				rockchip,pins = <0x01 0x11 0x00 0xb9>;
			};

			vsel2-gpio {
				rockchip,pins = <0x01 0x0e 0x00 0xb9>;
			};
		};

		sdio-pwrseq {

			wifi-enable-h {
				rockchip,pins = <0x00 0x0a 0x00 0xb0>;
				phandle = <0xba>;
			};
		};

		wifi {

			wifi-host-wake-l {
				rockchip,pins = <0x00 0x03 0x00 0xb0>;
				phandle = <0x26>;
			};
		};

		leds {

			user_led1 {
				rockchip,pins = <0x04 0x12 0x00 0xb0>;
				phandle = <0xbf>;
			};

			user_led2 {
				rockchip,pins = <0x04 0x16 0x00 0xb0>;
				phandle = <0xc0>;
			};

			user_led3 {
				rockchip,pins = <0x04 0x18 0x00 0xb0>;
				phandle = <0xc1>;
			};

			user_led4 {
				rockchip,pins = <0x04 0x1c 0x00 0xb0>;
				phandle = <0xc2>;
			};

			wlan_led {
				rockchip,pins = <0x04 0x1d 0x00 0xb0>;
				phandle = <0xc3>;
			};

			bt_led {
				rockchip,pins = <0x04 0x1e 0x00 0xb0>;
				phandle = <0xc4>;
			};
		};

		usb2 {

			host-vbus-drv {
				rockchip,pins = <0x04 0x19 0x00 0xb0>;
				phandle = <0xbd>;
			};
		};
	};

	opp-table0 {
		compatible = "operating-points-v2";
		opp-shared;
		phandle = <0x0b>;

		opp00 {
			opp-hz = <0x00 0x18519600>;
			opp-microvolt = "\0\f5";
			clock-latency-ns = <0x9c40>;
		};

		opp01 {
			opp-hz = <0x00 0x23c34600>;
			opp-microvolt = "\0\f5";
		};

		opp02 {
			opp-hz = <0x00 0x30a32c00>;
			opp-microvolt = <0xcf850>;
		};

		opp03 {
			opp-hz = <0x00 0x3c14dc00>;
			opp-microvolt = <0xe1d48>;
		};

		opp04 {
			opp-hz = <0x00 0x47868c00>;
			opp-microvolt = <0xf4240>;
		};

		opp05 {
			opp-hz = <0x00 0x54667200>;
			opp-microvolt = <0x112a88>;
		};
	};

	opp-table1 {
		compatible = "operating-points-v2";
		opp-shared;
		phandle = <0x0d>;

		opp00 {
			opp-hz = <0x00 0x18519600>;
			opp-microvolt = "\0\f5";
			clock-latency-ns = <0x9c40>;
		};

		opp01 {
			opp-hz = <0x00 0x23c34600>;
			opp-microvolt = "\0\f5";
		};

		opp02 {
			opp-hz = <0x00 0x30a32c00>;
			opp-microvolt = <0xc96a8>;
		};

		opp03 {
			opp-hz = <0x00 0x3c14dc00>;
			opp-microvolt = <0xd59f8>;
		};

		opp04 {
			opp-hz = <0x00 0x47868c00>;
			opp-microvolt = <0xe7ef0>;
		};

		opp05 {
			opp-hz = <0x00 0x54667200>;
			opp-microvolt = <0xfa3e8>;
		};

		opp06 {
			opp-hz = <0x00 0x5fd82200>;
			opp-microvolt = <0x10c8e0>;
		};

		opp07 {
			opp-hz = <0x00 0x6b49d200>;
			opp-microvolt = <0x124f80>;
		};
	};

	opp-table2 {
		compatible = "operating-points-v2";
		phandle = <0xae>;

		opp00 {
			opp-hz = <0x00 0xbebc200>;
			opp-microvolt = "\0\f5";
		};

		opp01 {
			opp-hz = <0x00 0x11b3dc40>;
			opp-microvolt = "\0\f5";
		};

		opp02 {
			opp-hz = <0x00 0x17d78400>;
			opp-microvolt = <0xc96a8>;
		};

		opp03 {
			opp-hz = <0x00 0x1dcd6500>;
			opp-microvolt = <0xd59f8>;
		};

		opp04 {
			opp-hz = <0x00 0x23c34600>;
			opp-microvolt = <0xe1d48>;
		};

		opp05 {
			opp-hz = <0x00 0x2faf0800>;
			opp-microvolt = <0x10c8e0>;
		};
	};

	sdio-pwrseq {
		compatible = "mmc-pwrseq-simple";
		clocks = <0x42 0x01>;
		clock-names = "ext_clock";
		pinctrl-names = "default";
		pinctrl-0 = <0xba>;
		reset-gpios = <0x25 0x0a 0x01>;
		phandle = <0x21>;
	};

	vcc12v-dcin {
		compatible = "regulator-fixed";
		regulator-name = "vcc12v_dcin";
		regulator-min-microvolt = <0xb71b00>;
		regulator-max-microvolt = <0xb71b00>;
		regulator-always-on;
		regulator-boot-on;
		phandle = <0xbb>;
	};

	vcc1v8-s0 {
		compatible = "regulator-fixed";
		regulator-name = "vcc1v8_s0";
		regulator-min-microvolt = <0x1b7740>;
		regulator-max-microvolt = <0x1b7740>;
		regulator-always-on;
		phandle = <0x8e>;
	};

	vcc5v0-sys {
		compatible = "regulator-fixed";
		regulator-name = "vcc5v0_sys";
		regulator-min-microvolt = <0x4c4b40>;
		regulator-max-microvolt = <0x4c4b40>;
		regulator-always-on;
		vin-supply = <0xbb>;
		phandle = <0x82>;
	};

	vcc3v3-sys {
		compatible = "regulator-fixed";
		regulator-name = "vcc3v3_sys";
		regulator-min-microvolt = <0x325aa0>;
		regulator-max-microvolt = <0x325aa0>;
		regulator-always-on;
		vin-supply = <0x82>;
		phandle = <0x1e>;
	};

	vcc3v3-pcie-regulator {
		compatible = "regulator-fixed";
		enable-active-high;
		pinctrl-names = "default";
		pinctrl-0 = <0xbc>;
		regulator-boot-on;
		regulator-name = "vcc3v3_pcie";
		regulator-min-microvolt = <0x325aa0>;
		regulator-max-microvolt = <0x325aa0>;
		vin-supply = <0x1e>;
		gpio = <0x1a 0x05 0x00>;
		phandle = <0x19>;
	};

	vcc5v0-host-regulator {
		compatible = "regulator-fixed";
		enable-active-high;
		pinctrl-names = "default";
		pinctrl-0 = <0xbd>;
		regulator-name = "vcc5v0_host";
		regulator-min-microvolt = <0x4c4b40>;
		regulator-max-microvolt = <0x4c4b40>;
		regulator-always-on;
		vin-supply = <0x82>;
		gpio = <0xbe 0x1a 0x00>;
		phandle = <0x90>;
	};

	vcc-0v9 {
		compatible = "regulator-fixed";
		regulator-name = "vcc_0v9";
		regulator-always-on;
		regulator-min-microvolt = <0xdbba0>;
		regulator-max-microvolt = <0xdbba0>;
		vin-supply = <0x1e>;
		phandle = <0x17>;
	};

	chosen {
		stdout-path = "serial2:1500000n8";
	};

	external-gmac-clock {
		compatible = "fixed-clock";
		clock-frequency = <0x7735940>;
		clock-output-names = "clkin_gmac";
		#clock-cells = <0x00>;
		phandle = <0x1d>;
	};

	leds {
		compatible = "gpio-leds";
		pinctrl-names = "default";
		pinctrl-0 = <0xbf 0xc0 0xc1 0xc2 0xc3 0xc4>;

		user_led1 {
			label = "ledl_ctl";
			gpios = <0xbe 0x1b 0x00>;
			linux,default-trigger = "activity";
		};

		user_led2 {
			label = "host5ven_gpio";
			gpios = <0x25 0x0c 0x00>;
			linux,default-trigger = "none";
			default-state = "on";
		};

		user_led3 {
			label = "green:ledl_ctl";
			gpios = <0x83 0x02 0x00>;
			linux,default-trigger = "none";
			default-state = "on";
		};

		user_led4 {
			label = "vcc5v0_host";
			gpios = <0x1a 0x0c 0x00>;
			panic-indicator;
			linux,default-trigger = "none";
		};

		wlan_active_led {
			label = "m12v_en";
			gpios = <0x83 0x17 0x00>;
			linux,default-trigger = "none";
			default-state = "on";
		};

		bt_active_led {
			label = "blue:bt";
			gpios = <0xbe 0x1e 0x00>;
			linux,default-trigger = "hci0-power";
			default-state = "off";
		};
	};
};
